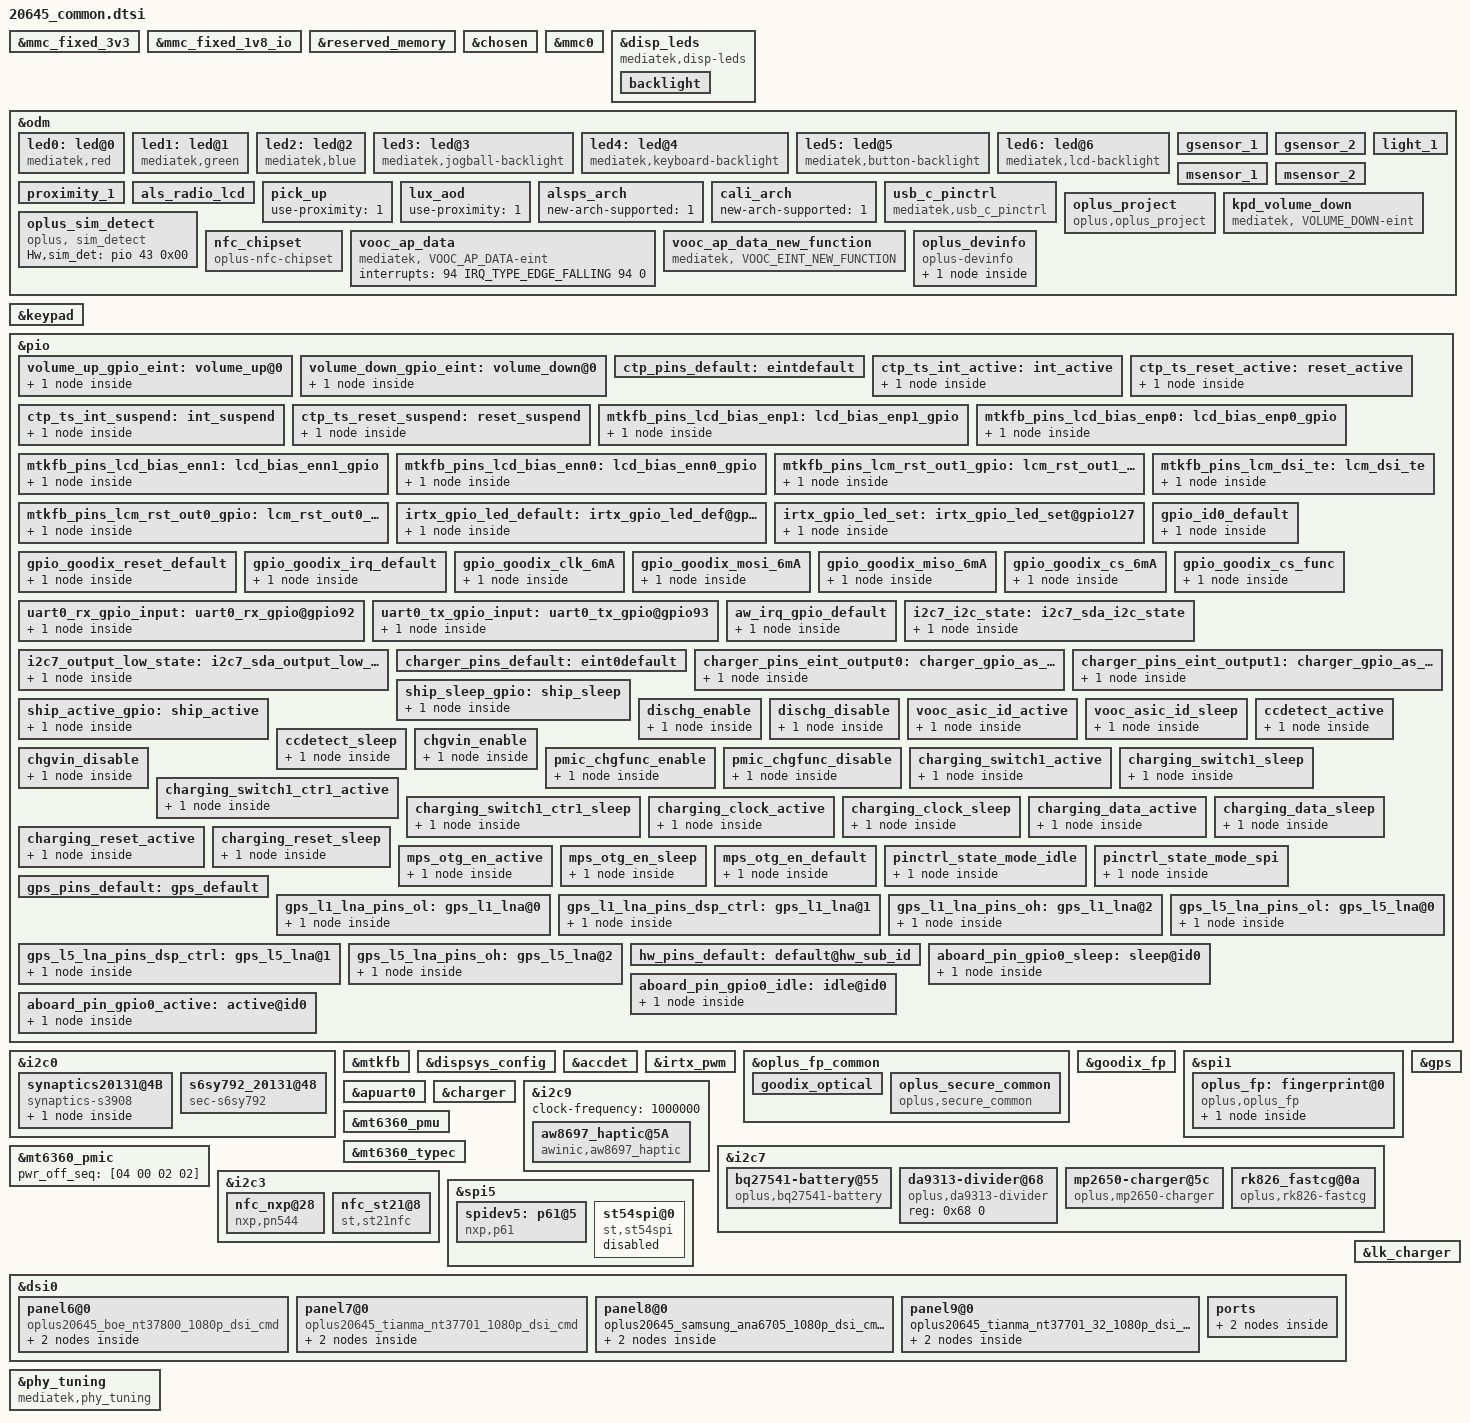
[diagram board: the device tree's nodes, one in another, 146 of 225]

&mmc_fixed_3v3 {
	status = "okay";
	regulator-name = "mmc_power";
	regulator-min-microvolt = <3300000>;
	regulator-max-microvolt = <3300000>;
	enable-active-high;
	regulator-always-on;
};

&mmc_fixed_1v8_io {
	status = "okay";
	regulator-name = "mmc_io";
	regulator-min-microvolt = <1800000>;
	regulator-max-microvolt = <1800000>;
	enable-active-high;
	regulator-always-on;
};

&reserved_memory {
};

/* chosen */
&chosen {

	atag,videolfb-fb_base_l = <0x7e020000>;
	atag,videolfb-fb_base_h = <0x0>;
	atag,videolfb-islcmfound = <1>;
	atag,videolfb-islcm_inited = <0>;
	atag,videolfb-fps= <6000>;
	atag,videolfb-vramSize= <0x1be0000>;
	atag,videolfb-lcmname=
		"nt35595_fhd_dsi_cmd_truly_nt50358_drv";
};

&mmc0 {
	status = "okay";
	/* pinctrl-names = "default", "state_uhs"; */
	/* pinctrl-0 = <&mmc0_pins_default>; */
	/* pinctrl-1 = <&mmc0_pins_uhs>; */
	bus-width = <8>;
	max-frequency = <5000000>;
	cap-mmc-highspeed;
	no-sdio;
	no-sd;
	vmmc-supply = <&mmc_fixed_3v3>;
	vqmmc-supply = <&mmc_fixed_1v8_io>;
	non-removable;
};

&disp_leds {
	compatible = "mediatek,disp-leds";
	backlight {
		label = "lcd-backlight";
		max-brightness = <4095>;
		led-bits = <12>;
		trans-bits = <12>;
		default-state = "on";
	};
};

&odm {
	led0:led@0 {
		compatible = "mediatek,red";
		led_mode = <0>;
		data = <1>;
		pwm_config = <0 0 0 0 0>;
	};
	led1:led@1 {
		compatible = "mediatek,green";
		led_mode = <0>;
		data = <1>;
		pwm_config = <0 0 0 0 0>;
	};
	led2:led@2 {
		compatible = "mediatek,blue";
		led_mode = <0>;
		data = <1>;
		pwm_config = <0 0 0 0 0>;
	};
	led3:led@3 {
		compatible = "mediatek,jogball-backlight";
		led_mode = <0>;
		data = <1>;
		pwm_config = <0 0 0 0 0>;
	};
	led4:led@4 {
		compatible = "mediatek,keyboard-backlight";
		led_mode = <0>;
		data = <1>;
		pwm_config = <0 0 0 0 0>;
	};
	led5:led@5 {
		compatible = "mediatek,button-backlight";
		led_mode = <0>;
		data = <1>;
		pwm_config = <0 0 0 0 0>;
	};
	led6:led@6 {
		compatible = "mediatek,lcd-backlight";
		//led_mode = <5>;
		//#else
		led_mode = <4>;
		//#endif
		data = <1>;
		pwm_config = <0 1 0 0 0>;
	};

/* sensor start */
	/*
	enum {
		LIS3DH,
		LSM6DS3,
		BMI160,
		LIS2HH12,
		LSM6DSM,
		BMI2XY,
		LSM6DSO,
	};
	*/
	gsensor_1: gsensor_1 {
		status = "okay";
		sensor_name = <2>;//BMI160
		device_name = "bmi160";
		i2c_num = <2>;
		i2c_addr = <0>;
		direction = <7>;
		eint_num = <3>;
		step_count_7_en = <1>;
		config_miso = <1>;
		correct_y_bias = <0>;
		gyro_cali_version= <2>;
		acc_cali_range= <250 250 250>; //250mg
	};
	gsensor_2: gsensor_2 {
		status = "okay";
		sensor_name = <4>;//LSM6DS3_c
		device_name = "lsm6ds3";
		i2c_num = <2>;
		i2c_addr = <0>;
		direction = <6>;
		eint_num = <3>;
		gyro_cali_version= <2>;
		acc_cali_range= <200 200 200>; //250mg
	};
	/*
	enum {
		AKM09911,
		MMC3530,
		MMC5603,
		MXG4300,
	};
	*/
	msensor_1: msensor_1 {
		status = "okay";
		sensor_name = <0>;//AKM09911
		i2c_num = <0>;
		i2c_addr = <12>;
		direction = <1>;
		eint_num = <0>;
		soft-mag-parameter = <11168 0 285 1 86 1 218 1 9025 0 78 1 263 1 31 0 10658 0>;
	};
	msensor_2: msensor_2 {
		status = "okay";
		sensor_name = <2>;//MMC5603
		i2c_num = <0>;
		i2c_addr = <48>;
		direction = <1>;
		eint_num = <0>;
		soft-mag-parameter = <9988 0 131 0 26 0 769 1 7569 0 105 1 417 0 234 1 9811 0>;
	};
	/*
	enum {
		TMD2725,
		APSD9922,
		STK3335,
		STK3331,
		STK2232,
		TCS3701,
		STK32600,
	};
	*/
	proximity_1: proximity_1 {
		status = "okay";
		sensor_name = <5>;//TCS3701
		i2c_num = <0>;
		i2c_addr = <57>;
		direction = <4>;
		eint_num = <4>;
		low_step = <300>;
		high_step = <400>;
		low_limit = <400>;
		high_limit = <600>;
		dirty_low_step = <100>;
		dirty_high_step = <150>;
		ps_dirty_limit = <1022>;
		ps_ir_limit = <500>;
		ps_adjust_min = <0>;
		ps_adjust_max = <600>;
		sampling_count = <5>;
		step_max = <400>;
		step_min = <110>;
		step_div = <1500>;
		anti_shake_delta = <80>;
		dynamic_cali_max = <1023>;
		raw2offset_radio = <31200>;
		offset_max = <250>;
		offset_range_min = <255>;
		offset_range_max = <255>;
		force_cali_limit = <2000>;
		cali_jitter_limit = <30>;
		cal_offset_margin = <120>;
	};
	light_1: light_1 {
		status = "okay";
		sensor_name = <5>;//TCS3701
		i2c_num = <0>;
		i2c_addr = <57>;
		direction = <4>;
		eint_num = <4>;
		als_ratio = <200>;
		als_buffer_length =<10>;
		als_type = <2>;
		device_name = "tcs3701";
	};
	als_radio_lcd:als_radio_lcd {
		status = "okay";
		samsung_als_radio = <200>;
		boe_als_radio = <150>;
		tianma_als_radio = <150>;
	};
	pick_up: pick_up {
		status = "okay";
		use-proximity = <1>;
	};
	lux_aod: lux_aod {
		status = "okay";
		use-proximity = <1>;
	};
	alsps_arch: alsps_arch {
		status = "okay";
		new-arch-supported = <1>;
	};
	cali_arch: cali_arch {
		status = "okay";
		new-arch-supported = <1>;
	};
/* sensor end */
	usb_c_pinctrl:usb_c_pinctrl {
		compatible = "mediatek,usb_c_pinctrl";
	};
/*OPLUS_FEATURE_TP_BASIC oplus project start */
	oplus_project:oplus_project {
		compatible = "oplus,oplus_project";
	};
/*endif*/
//#ifdef OPLUS_FEATURE_TP_BASIC
        kpd_volume_down:kpd_volume_down {
                compatible = "mediatek, VOLUME_DOWN-eint";
                interrupt-parent = <&pio>;
                interrupts = <155 IRQ_TYPE_EDGE_FALLING 155 0>;
                debounce = <32000>;
                status = "okay";
        };

//#endif OPLUS_FEATURE_TP_BASIC

//#ifdef OPLUS_FEATURE_TP_BASIC
    oplus_sim_detect {
        compatible = "oplus, sim_detect";
        Hw,sim_det = <&pio 43 0x00>;
    };
//#endif /* OPLUS_FEATURE_TP_BASIC */

    nfc_chipset:nfc_chipset {
        compatible = "oplus-nfc-chipset";
        chipset-20645 = "SN100T";
        chipset-20649 = "SN100T";
    };
//#endif /* OPLUS_FEATURE_NFC_CONSOFT */
};
//#ifdef OPLUS_FEATURE_TP_BASIC
&keypad {
        keypad,volume-up        = <&pio 20 0x00>;
        keypad,volume-down      = <&pio 155 0x00>;
        pinctrl-names = "volume_up_as_int", "volume_down_as_int";
        pinctrl-0 = <&volume_up_gpio_eint>;
        pinctrl-1 = <&volume_down_gpio_eint>;
        status = "okay";
};

&pio {
        volume_up_gpio_eint:volume_up@0{
                pins_cmd_dat {
                        pinmux = <PINMUX_GPIO59__FUNC_GPIO59>;
                        slew-rate = <0>;  /*direction 0:in, 1:out*/
                        input-enable;
                };
        };

        volume_down_gpio_eint:volume_down@0{
                pins_cmd_dat {
                        pinmux = <PINMUX_GPIO155__FUNC_GPIO155>;
                        slew-rate = <0>;  /*direction 0:in, 1:out*/
                        input-enable;
                };
        };
};
//#endif OPLUS_FEATURE_TP_BASIC
//#ifdef OPLUS_FEATURE_TP_BASIC
&i2c0 {

	synaptics20131@4B {
		compatible = "synaptics-s3908";
		reg = <0x4B>;
		chip-name = "S3908";

		/* Interrupt && Irq-gpio */
		interrupt-parent = <&pio>;
		interrupts = <21 0x2008>;

		/* Power Config */
		vdd_2v8-supply  = <&mt_pmic_vtp_ldo_reg>;
		vdd_2v8_volt = <3000000>;
		/* Other HW Resource */

		irq-gpio = <&pio 21 0x2008>;
		reset-gpio = <&pio 20 0x1>;
		pinctrl-names = "default";
		pinctrl-0 = <&ctp_ts_int_active &ctp_ts_reset_suspend>;

		touchpanel,max-num-support = <10>;
                touchpanel,tx-rx-num = <16 36>;
                touchpanel,panel-coords = <5400 12000>;
                touchpanel,display-coords = <1080 2400>;
                touchpanel,touchmajor-limit = <160 270>;
		//touchpanel,elimination-range = <20 200 200>;
                touchpanel,int-mode = <1>; /*0: interrupt and disable, 1:interrupt and not disable*/
		touchpanel,smooth-level = <0 1 2 3 8 10>;
		touchpanel,sensitive-level = <0 88 70 64 45 10>;

		vid_len = <2>;
		tp_type = <3>; /*type:8 BOE*/
		platform_support_project = <20645 20649 0x2064A 0x2068D
                				20645 20649 0x2064A 0x2068D>;
		platform_support_project_dir = <20645 20645 20645 20645
                				20645 20645 20645 20645>;
		platform_support_project_commandline = "oplus20645_boe_nt37800_1080p_dsi_cmd","oplus20645_boe_nt37800_1080p_dsi_cmd","oplus20645_boe_nt37800_1080p_dsi_cmd","oplus20645_boe_nt37800_1080p_dsi_cmd","oplus20645_tianma_nt37701","oplus20645_tianma_nt37701","oplus20645_tianma_nt37701","oplus20645_tianma_nt37701";

		prevention,dead_area_width = <0 0>;
		prevention,makeup_cnt_weight = <4 1 2 2 1>;
		prevention,large_judge_para = <30 8 8>;
		prevention,large_corner_judge_para = <30 5 5 80 80 0>;

		prevention,curved_large_area_width = <500 500 400 3 3>;
		prevention,large_curved_long_judge_para = <7 180 30 15 15 7 4 7 5 3 3>;
		prevention,large_curved_short_judge_para = <6 180 30 0 15 7 4 7 5 2 3>;
		prevention,grip_large_detect_time = <175>;
		prevention,grip_down_delta_time = <150>;
		prevention,curved_screen;

		prevention,condition_judge_para = <40 30>;
		prevention,condition_area_width = <0 0 80 80>;
		prevention,large_area_width = <0 0>;
		prevention,large_corner_width = <0 0 0>;
		prevention,eli_area_width = <0 0 0 0 0 0>;
		prevention,grip_disable_level = <6>;

		/* SW Support Feature Control */
		health_monitor_v2_support;
		black_gesture_support;
		charger_pump_support;
		lcd_tp_refresh_support;
		fw_update_app_support;
		smart_gesture_support;
		game_switch_support;
		report_flow_unlock_support;
		kernel_grip_support;
		fingerprint_underscreen_support;
		headset_pump_support;
		pressure_report_support;
		irq_need_dev_resume_ok;
		touchpanel,single-optimized-time = <8>;
		report_rate_white_list_support;
		/*
		 *Virtual Key Config:
		 *1:touchpanel,button-type: <virtualkey_type  supportted_button-map>
		 *virtualkey_type:
		 *Type 1: using board_properties
		 *Type 2: using same IC (button zone&& touch zone are seprate)
		 *Type 3: using diffrent IC (button zone&& touch zone are seprate)
		 *Type 4: No need of virtual key process
		 *supportted_button-map:select|menu|home|back
		 *
		 *2:touchpanel,button-map
		 *type (X1,Y1)(X2,Y2)(X3,Y3)(Width_X,Hight_Y)--Only when button-type is 0
		 */
		touchpanel,button-type = <4>;
		touchpanel.button-TRx = <0 0>;

		S3908 {
			report_rate_default = <90>;
			report_rate_game_value = <2>;
		};
	};

	s6sy792_20131@48 {
		compatible = "sec-s6sy792";
		reg = <0x48>;
		chip-name = "S6SY792";

                /* Interrupt && Irq-gpio */
                interrupt-parent = <&pio>;
                interrupts = <21 0x2008>;

                /* Power Config */
                vdd_2v8-supply  = <&mt_pmic_vtp_ldo_reg>;
                vdd_2v8_volt = <3000000>;
                /* Other HW Resource */

                irq-gpio = <&pio 21 0x2008>;
                reset-gpio = <&pio 20 0x1>;
                pinctrl-names = "default";
                pinctrl-0 = <&ctp_ts_int_active &ctp_ts_reset_suspend>;

		touchpanel,max-num-support = <10>;
                touchpanel,tx-rx-num = <16 36>;
                touchpanel,panel-coords = <5400 12000>;
                touchpanel,display-coords = <1080 2400>;
                touchpanel,touchmajor-limit = <160 270>;
                //touchpanel,elimination-range = <20 200 200>;
		touchpanel,smooth-level = <255 0 2 4 5 6>;
		touchpanel,smooth-level-charging = <255 9 10 10 11 11>;
		touchpanel,sensitive-level = <255 20 15 10 5 1>;

                vid_len = <2>;
                tp_type = <8>; /*type:8 SAMSUNG*/
                platform_support_project = <20645 20649 0x2064A 0x2068D>;
        	platform_support_project_dir = <20645 20645 20645 20645>;
                platform_support_project_commandline = "oplus20645_samsung_ana6705_1080p_dsi_cmd","oplus20645_samsung_ana6705_1080p_dsi_cmd","oplus20645_samsung_ana6705_1080p_dsi_cmd","oplus20645_samsung_ana6705_1080p_dsi_cmd";

		prevention,dead_area_width = <0 0>;
		prevention,makeup_cnt_weight = <4 1 2 2 1>;
		prevention,large_judge_para = <30 8 8>;
		prevention,large_corner_judge_para = <30 5 5 80 80 0>;

		prevention,curved_large_area_width = <500 500 400 3 3>;
		prevention,large_curved_long_judge_para = <6 180 30 15 15 7 4 7 5 3 3>;
		prevention,large_curved_short_judge_para = <6 180 30 0 15 7 4 7 5 2 3>;
		prevention,grip_large_detect_time = <175>;
		prevention,grip_down_delta_time = <125>;
		prevention,curved_screen;

		prevention,condition_judge_para = <40 30>;
		prevention,condition_area_width = <0 0 80 80>;
		prevention,large_area_width = <0 0>;
		prevention,large_corner_width = <0 0 0>;
		prevention,eli_area_width = <0 0 0 0 0 0>;
		prevention,grip_disable_level = <6>;

		/* SW Support Feature Control */
		health_monitor_v2_support;
		black_gesture_support;
		charger_pump_support;
		fw_update_app_support;
		smart_gesture_support;
		game_switch_support;
		kernel_grip_support;
		fingerprint_underscreen_support;
		headset_pump_support;
		pressure_report_support;
		irq_need_dev_resume_ok;
		sec_kernel_grip_para = <21000>;
		auto_test_need_cal_support;
		touchpanel,single-optimized-time = <8>;

                /*
                 *Virtual Key Config:
                 *1:touchpanel,button-type: <virtualkey_type  supportted_button-map>
                 *virtualkey_type:
                 *Type 1: using board_properties
                 *Type 2: using same IC (button zone&& touch zone are seprate)
                 *Type 3: using diffrent IC (button zone&& touch zone are seprate)
                 *Type 4: No need of virtual key process
                 *supportted_button-map:select|menu|home|back
                 *
                 *2:touchpanel,button-map
                 *type (X1,Y1)(X2,Y2)(X3,Y3)(Width_X,Hight_Y)--Only when button-type is 0
                 */
                touchpanel,button-type = <4>;
                touchpanel.button-TRx = <0 0>;
	};
};

&pio {
	ctp_pins_default: eintdefault {
	};
	ctp_ts_int_active: int_active {
		pins_cmd_dat {
			pinmux = <PINMUX_GPIO21__FUNC_GPIO21>;
			slew-rate = <0>;
			bias-pull-up;
		};
	};
	ctp_ts_reset_active: reset_active {
		pins_cmd_dat {
			pinmux = <PINMUX_GPIO20__FUNC_GPIO20>;
			slew-rate = <1>;
			output-high;
		};
	};
	ctp_ts_int_suspend: int_suspend {
		pins_cmd_dat {
			pinmux = <PINMUX_GPIO21__FUNC_GPIO21>;
			slew-rate = <1>;
			output-low;
		};
	};
	ctp_ts_reset_suspend: reset_suspend {
		pins_cmd_dat {
			pinmux = <PINMUX_GPIO20__FUNC_GPIO20>;
			slew-rate = <1>;
			output-low;
		};
	};
};
//#endif OPLUS_FEATURE_TP_BASIC

/* DISPSYS GPIO standardization */
&pio {
	mtkfb_pins_lcd_bias_enp1: lcd_bias_enp1_gpio {
		pins_cmd_dat {
			pinmux = <PINMUX_GPIO28__FUNC_GPIO28>;
			slew-rate = <1>;
			output-high;
		};
	};

	mtkfb_pins_lcd_bias_enp0: lcd_bias_enp0_gpio {
		pins_cmd_dat {
			pinmux = <PINMUX_GPIO28__FUNC_GPIO28>;
			slew-rate = <1>;
			output-low;
		};
	};

	mtkfb_pins_lcd_bias_enn1: lcd_bias_enn1_gpio {
		pins_cmd_dat {
			pinmux = <PINMUX_GPIO29__FUNC_GPIO29>;
			slew-rate = <1>;
			output-high;
		};
	};

	mtkfb_pins_lcd_bias_enn0: lcd_bias_enn0_gpio {
		pins_cmd_dat {
			pinmux = <PINMUX_GPIO29__FUNC_GPIO29>;
			slew-rate = <1>;
			output-low;
		};
	};

	mtkfb_pins_lcm_rst_out1_gpio: lcm_rst_out1_gpio {
		pins_cmd_dat {
			pinmux = <PINMUX_GPIO42__FUNC_GPIO42>;
			slew-rate = <1>;
			output-high;
		};
	};

	mtkfb_pins_lcm_rst_out0_gpio: lcm_rst_out0_gpio {
		pins_cmd_dat {
			pinmux = <PINMUX_GPIO42__FUNC_GPIO42>;
			slew-rate = <1>;
			output-low;
		};
	};

	mtkfb_pins_lcm_dsi_te: lcm_dsi_te {
		pins_cmd_dat {
			pinmux = <PINMUX_GPIO41__FUNC_DSI_TE>;
		};
	};
};

&mtkfb {
	pinctrl-names = "lcd_bias_enp1_gpio", "lcd_bias_enp0_gpio",
		"lcd_bias_enn1_gpio", "lcd_bias_enn0_gpio",
		"lcm_rst_out1_gpio", "lcm_rst_out0_gpio",
		"mode_te_te";
	pinctrl-0 = <&mtkfb_pins_lcd_bias_enp1>;
	pinctrl-1 = <&mtkfb_pins_lcd_bias_enp0>;
	pinctrl-2 = <&mtkfb_pins_lcd_bias_enn1>;
	pinctrl-3 = <&mtkfb_pins_lcd_bias_enn0>;
	pinctrl-4 = <&mtkfb_pins_lcm_rst_out1_gpio>;
	pinctrl-5 = <&mtkfb_pins_lcm_rst_out0_gpio>;
	pinctrl-6 = <&mtkfb_pins_lcm_dsi_te>;
	status = "okay";
};

&dispsys_config {
	pinctrl-names =
		"lcm_rst_out1_gpio", "lcm_rst_out0_gpio",
		"mode_te_te";
	pinctrl-0 = <&mtkfb_pins_lcm_rst_out1_gpio>;
	pinctrl-1 = <&mtkfb_pins_lcm_rst_out0_gpio>;
	pinctrl-2 = <&mtkfb_pins_lcm_dsi_te>;
	status = "okay";

	helper-value = <0>, /*MTK_DRM_OPT_STAGE*/
		<1>, /*MTK_DRM_OPT_USE_CMDQ*/
		<1>, /*MTK_DRM_OPT_USE_M4U*/
		<0>, /*MTK_DRM_OPT_SODI_SUPPORT*/
		<1>, /*MTK_DRM_OPT_IDLE_MGR*/
		<0>, /*MTK_DRM_OPT_IDLEMGR_SWTCH_DECOUPLE*/
		<1>, /*MTK_DRM_OPT_IDLEMGR_BY_REPAINT*/
		<0>, /*MTK_DRM_OPT_IDLEMGR_ENTER_ULPS*/
		<0>, /*MTK_DRM_OPT_IDLEMGR_KEEP_LP11*/
		<0>, /*MTK_DRM_OPT_DYNAMIC_RDMA_GOLDEN_SETTING*/
		<1>, /*MTK_DRM_OPT_IDLEMGR_DISABLE_ROUTINE_IRQ*/
		<0>, /*MTK_DRM_OPT_MET_LOG*/
		<1>, /*MTK_DRM_OPT_USE_PQ*/
		<1>, /*MTK_DRM_OPT_ESD_CHECK_RECOVERY*/
		<1>, /*MTK_DRM_OPT_ESD_CHECK_SWITCH*/
		<1>, /*MTK_DRM_OPT_PRESENT_FENCE*/
		<0>, /*MTK_DRM_OPT_RDMA_UNDERFLOW_AEE*/
		<0>, /*MTK_DRM_OPT_DSI_UNDERRUN_AEE*/
		<1>, /*MTK_DRM_OPT_HRT*/
		<1>, /*MTK_DRM_OPT_HRT_MODE*/
		<0>, /*MTK_DRM_OPT_DELAYED_TRIGGER*/
		<1>, /*MTK_DRM_OPT_OVL_EXT_LAYER*/
		<0>, /*MTK_DRM_OPT_AOD*/
		<1>, /*MTK_DRM_OPT_RPO*/
		<0>, /*MTK_DRM_OPT_DUAL_PIPE*/
		<0>, /*MTK_DRM_OPT_DC_BY_HRT*/
		<1>, /*MTK_DRM_OPT_OVL_WCG*/
		<0>, /*MTK_DRM_OPT_OVL_SBCH*/
		<1>, /*MTK_DRM_OPT_COMMIT_NO_WAIT_VBLANK*/
		<0>, /*MTK_DRM_OPT_MET*/
		<0>, /*MTK_DRM_OPT_REG_PARSER_RAW_DUMP*/
		<0>, /*MTK_DRM_OPT_VP_PQ*/
		<0>, /*MTK_DRM_OPT_GAME_PQ*/
		<0>, /*MTK_DRM_OPT_MMPATH*/
		<1>, /*MTK_DRM_OPT_HBM*/
		<0>, /*MTK_DRM_OPT_VDS_PATH_SWITCH*/
		<0>, /*MTK_DRM_OPT_LAYER_REC*/
		<1>, /*MTK_DRM_OPT_CLEAR_LAYER*/
		<1>, /*MTK_DRM_OPT_SF_PF*/
		<1>, /*MTK_DRM_OPT_PRIM_DUAL_PIPE*/
		<1>; /*MTK_DRM_OPT_DYN_MIPI_CHANGE*/
};
/* DISPSYS GPIO standardization end */

/* accdet start */
&accdet {
	/* accdet micbias voltage: 0x09:2.85v 0x08:2.8v 0x07,
	 * 2.7v;0x05,2.5v;0x02,1.9v
	 */
	accdet-mic-vol = <8>;
	/* accdet pwm_width, pwm_thresh, fall_delay, rise_delay
	 * debounce0, debounce1, debounce3, debounce4
	 * eint pwm_width, eint pwm_thresh
	 * eint deb(debounce0, debounce1, debounce2, debounce3), inv_debounce
	 */
	/*#ifdef OPLUS_ARCH_EXTENDS*/
	headset-mode-setting = <0x500 0x500 1 0x1f0
				0x2000 0x800 0x2000 0x44
				0x0 0x7
				0x5 0x9 0x9 0xd 0xe>;
	/*#else*/
	/*
	headset-mode-setting = <0x500 0x500 1 0x1f0
				0x800 0x800 0x20 0x44
				0x4 0x1
				0x5 0x3 0x3 0x5 0xe>;
	*/
	/*#endif OPLUS_ARCH_EXTENDS*/
	accdet-plugout-debounce = <1>;
	/*1:ACC mode, 2:low cost without in bias, 6:low cost with in bias*/
	accdet-mic-mode = <2>;
	/*0--MD_MAX--UP_MAX--DW_MAX*/
	/*#ifdef OPLUS_ARCH_EXTENDS*/
	headset-three-key-threshold = <0 82 170 306>;
	/*#else*/
	/*headset-three-key-threshold = <0 80 220 400>;*/
	/*#endif OPLUS_ARCH_EXTENDS*/
	headset-three-key-threshold-CDD = <0 121 192 600>;
	/*0--MD_MAX--VOICE_MAX--UP_MAX--DW_MAX*/
	headset-four-key-threshold = <0 58 121 192 400>;

	/* select VTH to 2v and 500k, use internal resitance */
	eint_use_ext_res = <0>;
	status = "okay";
	/* add that is to rm the unplug headset pop */
	remove_unplug_pop = <1>;
};
/* accdet end */

/* IRTX GPIO Start */
&irtx_pwm {
	pinctrl-names = "irtx_gpio_led_default", "irtx_gpio_led_set";
	pinctrl-0 = <&irtx_gpio_led_default>;
	pinctrl-1 = <&irtx_gpio_led_set>;
	status = "okay";
};
&pio {
	/* IRTX GPIO Settings -Start */
	/* default: GPIO0, output, high */
	irtx_gpio_led_default:irtx_gpio_led_def@gpio127 {
		pins_cmd_dat {
			pinmux = <PINMUX_GPIO127__FUNC_GPIO127>;
			slew-rate = <1>;
			bias-disable;
			output-low;
			input-schmitt-enable = <0>;
		};
	};

	irtx_gpio_led_set:irtx_gpio_led_set@gpio127 {
		pins_cmd_dat {
			pinmux = <PINMUX_GPIO127__FUNC_PWM_3>;
			slew-rate = <1>;
			output-high;
		};
	};
}; /* IRTX GPIO Settings -End */

/* FINGERPRINT start */
&oplus_fp_common {
    oplus,fp_gpio_num = <1>;
    oplus,fp_gpio_0 = <&pio 190 0x0>;
    pinctrl-names = "default";
    pinctrl-0 = <&gpio_id0_default>;
    goodix_optical {
        oplus,fp-id = <0>; // fp id mapping table
        vendor-chip = <11>; // please refer to the struct fp_vendor_t in oplus_fp_commmon.n
        eng-menu = "-1,-1"; // represents SNR, inclination test item in engineer menu, and 0/1 means off/on 
        chip-name = "G_OPTICAL_G3S";  // /proc/fp_id, will be displayed in engineer menu 
	};


//#ifdef OPLUS_FEATURE_SECURITY_COMMON
	oplus_secure_common:oplus_secure_common {
		compatible = "oplus,secure_common";
		oplus,sec_reg_num = <0>;
		oplus,sec_en_anti_reg = <0>;
		oplus,sec_override1_reg = <0>;
		oplus,override1_en_value = <0>;
	};
//#endif  OPLUS_FEATURE_SECURITY_COMMON

};

&pio{
	gpio_id0_default: gpio_id0_default {
		pins_cmd_dat {
			pinmux = <PINMUX_GPIO190__FUNC_GPIO190>;
			slew-rate = <0>;
			bias-pull-up = <00>;
			input-enable;
		};
	};
};

&goodix_fp {
	goodix,gpio_irq = <&pio 15 0x00>;
	goodix,gpio_reset = <&pio 14 0x00>;
	goodix,gpio_cs = <&pio 157 0x00>;
	pinctrl-names = "default", "gf_spi_drive_6mA", "gf_cs_func";
	pinctrl-0 = <&gpio_goodix_irq_default>, <&gpio_goodix_reset_default>;
	pinctrl-1 = <&gpio_goodix_clk_6mA>, <&gpio_goodix_mosi_6mA>, <&gpio_goodix_miso_6mA>, <&gpio_goodix_cs_6mA>;
	pinctrl-2 = <&gpio_goodix_cs_func>;
	status = "okay";
};

&spi1 {
#address-cells = <1>;
#size-cells = <0>;
status = "okay";
oplus_fp: fingerprint@0 {
		 compatible = "oplus,oplus_fp";
		 reg = <0>;
		 spi-max-frequency = <8000000>;
		 spi-id = <1>;
		 spi-irq = <15>;
		 spi-reg = <11010000>;
		 dvdd-supply = <&mt_pmic_vmch_ldo_reg>;
		 dvdd-config = <3300000 3300000 150000>;
		 power-num = <1>;
		 status = "okay";
		 power_source_1 {
			 power-mode = <1>;
			 power-name = "dvdd";
			 power-config = "dvdd-config";
			 delay-time = <0>;
		 };
	 };
};
// 1 = ldo power, refer to oplus_fp_common.h
&pio{
gpio_goodix_reset_default: gpio_goodix_reset_default {
				   pins_cmd_dat {
					   pinmux = <PINMUX_GPIO14__FUNC_GPIO14>;
					   slew-rate = <1>;
					   output-low;
				   };
			   };
gpio_goodix_irq_default: gpio_goodix_irq_default {
				 pins_cmd_dat {
					 pinmux = <PINMUX_GPIO15__FUNC_GPIO15>;
					 slew-rate = <0>;
					 bias-pull-down;
				 };
			 };
gpio_goodix_clk_6mA: gpio_goodix_clk_6mA {
			     pins_cmd_dat {
				      pinmux = <PINMUX_GPIO156__FUNC_SPI1_A_CLK>;
				      drive-strength = <2>;
			     };
		     };
gpio_goodix_mosi_6mA: gpio_goodix_mosi_6mA {
			      pins_cmd_dat {
				      pinmux = <PINMUX_GPIO159__FUNC_SPI1_A_MO>;
				      drive-strength = <2>;
			      };
		      };
gpio_goodix_miso_6mA: gpio_goodix_miso_6mA {
			      pins_cmd_dat {
				      pinmux = <PINMUX_GPIO158__FUNC_SPI1_A_MI>;
				      drive-strength = <3>;
			      };
		      };
gpio_goodix_cs_6mA: gpio_goodix_cs_6mA {
			    pins_cmd_dat {
				    pinmux = <PINMUX_GPIO157__FUNC_SPI1_A_CSB>;
				    drive-strength = <2>;
			    };
		    };
gpio_goodix_cs_func: gpio_goodix_cs_func {
			     pins_cmd_dat {
				     pinmux = <PINMUX_GPIO157__FUNC_SPI1_A_CSB>;
				     drive-strength = <2>;
			     };
		     };
};
//#endif
/* FINGERPRINT end */

&apuart0 {
	pinctrl-names = "uart0_rx_gpio",
			"uart0_tx_gpio";
	pinctrl-0 = <&uart0_rx_gpio_input>;
	pinctrl-1 = <&uart0_tx_gpio_input>;
	status = "okay";
};

&pio {
	uart0_rx_gpio_input:uart0_rx_gpio@gpio92 {
		pins_cmd_dat {
			pinmux = <PINMUX_GPIO92__FUNC_GPIO92>;
			input-enable;
			slew-rate = <0>;
			bias-disable;
		};
	};
	uart0_tx_gpio_input:uart0_tx_gpio@gpio93 {
		pins_cmd_dat {
			pinmux = <PINMUX_GPIO93__FUNC_GPIO93>;
			input-enable;
			slew-rate = <0>;
			bias-disable;
		};
	};
};

&charger {
	io-channels = <&auxadc 4>,
		<&auxadc 5>;
	io-channel-names = "auxadc4-usb_temp_v_l",
		"auxadc5-usb_temp_v_r";

	pinctrl-names = "default", "charger_gpio_as_output_low", "charger_gpio_as_output_high", "ship_sleep", "ship_active",
		"dischg_enable", "dischg_disable", "chgvin_enable", "chgvin_disable", "pmic_chgfunc_enable", "pmic_chgfunc_disable",
		"ccdetect_active","ccdetect_sleep";
	pinctrl-0 = <&charger_pins_default>;
	pinctrl-1 = <&charger_pins_eint_output0>;	//USB_ON -> USB_SWITCH:(UART && USB)
	pinctrl-2 = <&charger_pins_eint_output1>;
	pinctrl-3 = <&ship_sleep_gpio>;				//ship_mode
	pinctrl-4 = <&ship_active_gpio>;
	pinctrl-5 = <&dischg_enable>;				//usb_hightemp_port
	pinctrl-6 = <&dischg_disable>;
	pinctrl-7 = <&chgvin_enable>;					//EVB GPIO30 chgvin
	pinctrl-8 = <&chgvin_disable>;
	pinctrl-9 = <&pmic_chgfunc_enable>;				//EVB GPIO26 chg_enable
	pinctrl-10 = <&pmic_chgfunc_disable>;
	//pinctrl-5 = <&shortc_active_gpio>;
	pinctrl-11 = <&ccdetect_active>;
	pinctrl-12 = <&ccdetect_sleep>;
	qcom,hv_flashled_support;
	qcom,chargerid_support;
	qcom,smart_charging_screenoff;
	qcom,usbtemp_batttemp_gap = <18>;
	qcom,input_current_charger_ma = <2000>;
	qcom,pd_input_current_charger_ma = <2000>;
	qcom,qc_input_current_charger_ma = <2000>;
	qcom,input_current_usb_ma = <500>;

	qcom,input_current_led_ma = <1200>;
	qcom,input_current_led_ma_high = <1200>;
	qcom,input_current_led_ma_warm = <1500>;
	qcom,input_current_led_ma_normal = <2000>;
	qcom,led_warm_bat_decidegc = <350>;
	qcom,led_high_bat_decidegc = <370>;

	qcom,input_current_camera_ma = <1200>;
	qcom,input_current_cdp_ma = <1500>;

	qcom,input_current_vooc_led_ma_high = <1200>;
	qcom,input_current_vooc_led_ma_warm = <1800>;
	qcom,input_current_vooc_led_ma_normal = <3600>;
	qcom,input_current_vooc_ma_normal = <3600>;
	qcom,vooc_temp_bat_normal_decidegc = <350>;
	qcom,input_current_vooc_ma_warm = <3200>;
	qcom,vooc_temp_bat_warm_decidegc = <370>;
	qcom,input_current_vooc_ma_high = <2200>;
	qcom,vooc_temp_bat_hot_decidegc = <440>;

	qcom,charger_current_vooc_ma_normal = <1800>;

	qcom,chg_ctrl_by_calling;
	qcom,input_current_calling_ma = <1500>;

	qcom,overtemp_bat_decidegc = <350>;
	qcom,iterm_disabled = <0>;
	sw_full_count = <25>;
	qcom,iterm_ma = <125>;
	qcom,recharge-mv = <100>;
	qcom,batt_capacity_mah = <4500>;/*typical capacity*/

	qcom,removed_bat_decidegc = <190>;  /*<-19C*/

	qcom,cold_bat_decidegc = <20>;  /*-2C~0C*/
	qcom,temp_cold_vfloat_mv = <3980>;
	qcom,temp_cold_fastchg_current_ma = <300>;

	qcom,little_cold_bat_decidegc = <0>;    /*0C~5C*/
	qcom,temp_little_cold_vfloat_mv = <4435>;
	qcom,temp_little_cold_fastchg_current_ma_high = <1100>;
	qcom,temp_little_cold_fastchg_current_ma_low = <1100>;
	qcom,temp_little_cold_fastchg_current_ma = <920>;
	qcom,pd_temp_little_cold_fastchg_current_ma_high = <2000>;
	qcom,pd_temp_little_cold_fastchg_current_ma_low = <1400>;
	qcom,qc_temp_little_cold_fastchg_current_ma_high = <2000>;
	qcom,qc_temp_little_cold_fastchg_current_ma_low = <1400>;

	qcom,cool_bat_decidegc = <50>;  /*5C~12C*/
	qcom,temp_cool_vfloat_mv = <4435>;
	qcom,temp_cool_fastchg_current_ma_high = <1100>;
	qcom,temp_cool_fastchg_current_ma_low = <1100>;
	qcom,pd_temp_cool_fastchg_current_ma_high = <2000>;
	qcom,pd_temp_cool_fastchg_current_ma_low = <2000>;
	qcom,qc_temp_cool_fastchg_current_ma_high = <2000>;
	qcom,qc_temp_cool_fastchg_current_ma_low = <2000>;

	qcom,little_cool_bat_decidegc = <120>;  /*12C~16C*/
	qcom,temp_little_cool_vfloat_mv = <4435>;
	qcom,temp_little_cool_fastchg_current_ma = <1100>;
	qcom,pd_temp_little_cool_fastchg_current_ma = <2000>;
	qcom,qc_temp_little_cool_fastchg_current_ma = <2000>;

	qcom,normal_bat_decidegc = <160>;       /*16C~44C*/
	qcom,temp_normal_fastchg_current_ma = <2000>;
	qcom,temp_normal_vfloat_mv = <4435>;
	qcom,pd_temp_normal_fastchg_current_ma = <2000>;
	qcom,qc_temp_normal_fastchg_current_ma = <2000>;

	qcom,warm_bat_decidegc = <450>;         /*45C~53C*/ /*8pin Bat Vooc project need add 3 degree C*/
	qcom,temp_warm_vfloat_mv = <4130>;
	qcom,temp_warm_fastchg_current_ma = <600>;
	qcom,pd_temp_warm_fastchg_current_ma = <600>;
	qcom,qc_temp_warm_fastchg_current_ma = <600>;
	qcom,temp_warm_fastchg_current_ma_led_on = <250>;

	qcom,hot_bat_decidegc = <530>;

	qcom,non_standard_vfloat_mv = <3980>;
	qcom,non_standard_fastchg_current_ma = <512>;

	qcom,short_c_bat_cv_mv = <4330>;
	qcom,short_c_bat_vfloat_mv = <3800>;
	qcom,short_c_bat_fastchg_current_ma = <512>;

	qcom,cold_vfloat_sw_limit = <3930>;
	qcom,little_cold_vfloat_sw_limit = <4385>;
	qcom,cool_vfloat_sw_limit = <4385>;
	qcom,little_cool_vfloat_sw_limit = <4385>;
	qcom,normal_vfloat_sw_limit = <4385>;
	qcom,warm_vfloat_sw_limit = <4080>;
	qcom,non_standard_vfloat_sw_limit = <3930>;
	qcom,short_c_bat_vfloat_sw_limit = <3750>;

	qcom,max_chg_time_sec = <60480>;
	qcom,charger_hv_thr = <9900>;
	qcom,charger_recv_thr = <9500>;
	qcom,charger_lv_thr = <3400>;
	qcom,vbatt_full_thr = <4435>;
	qcom,vbatt_hv_thr = <4600>;
	qcom,vfloat_step_mv = <8>;
	qcom,non_standard_vfloat_over_sw_limit = <3990>;
	qcom,cold_vfloat_over_sw_limit = <3990>;
	qcom,little_cold_vfloat_over_sw_limit = <4445>;
	qcom,cool_vfloat_over_sw_limit = <4445>;
	qcom,little_cool_vfloat_over_sw_limit = <4445>;
	qcom,normal_vfloat_over_sw_limit = <4445>;
	qcom,warm_vfloat_over_sw_limit = <4140>;

	qcom,vbatt_power_off = <3300>;
	qcom,vbatt_soc_1 = <3310>;
	qcom,vooc_project = <3>;
	qcom,vbatt_num = <2>;
	qcom,new_ui_warning_support;
	qcom,ffc_support;
	qcom,dual_ffc;
	recharge_after_full;

	qcom,normal_vterm_hw_inc = <18>;
	qcom,non_normal_vterm_hw_inc = <18>;

	qcom,ff1_normal_fastchg_ma = <550>;
	qcom,ff1_warm_fastchg_ma = <550>;

	qcom,ffc2_normal_fastchg_ma = <350>;/*12C~35c*/
	qcom,ffc2_temp_warm_decidegc = <350>;
	qcom,ffc2_warm_fastchg_ma = <350>;/*35C~40c*/
	qcom,ffc2_temp_high_decidegc = <400>;
	qcom,ffc2_temp_low_decidegc = <120>;

	qcom,ff1_exit_step_ma = <150>;
	qcom,ff1_warm_exit_step_ma = <150>;
	qcom,ffc2_exit_step_ma = <150>;
	qcom,ffc2_warm_exit_step_ma = <150>;

	qcom,ffc_normal_vfloat_sw_limit = <4445>;	/*exit*/
	qcom,ffc_temp_normal_vfloat_mv = <4500>;	/*vfloat*/
	qcom,ffc_normal_vfloat_over_sw_limit = <4500>;	/*vfloat*/

	qcom,ffc_warm_vfloat_sw_limit = <4445>;
	qcom,ffc_temp_warm_vfloat_mv = <4500>;
	qcom,ffc_warm_vfloat_over_sw_limit = <4500>;

	qcom,ffc2_normal_vfloat_sw_limit = <4440>;
	qcom,ffc2_temp_normal_vfloat_mv = <4500>;
	qcom,ffc2_normal_vfloat_over_sw_limit = <4500>;

	qcom,ffc2_warm_vfloat_sw_limit = <4435>;
	qcom,ffc2_temp_warm_vfloat_mv = <4500>;
	qcom,ffc2_warm_vfloat_over_sw_limit = <4500>;

	qcom,default_iterm_ma = <125>;
	qcom,default_temp_normal_fastchg_current_ma = <1000>;
	qcom,default_normal_vfloat_sw_limit = <4385>;
	qcom,default_temp_normal_vfloat_mv = <4435>;
	qcom,default_normal_vfloat_over_sw_limit = <4445>;

	qcom,default_temp_little_cool_fastchg_current_ma = <1100>;
	qcom,default_little_cool_vfloat_sw_limit = <4385>;
	qcom,default_temp_little_cool_vfloat_mv = <4435>;
	qcom,default_little_cool_vfloat_over_sw_limit = <4445>;

	qcom,vooc_show_ui_soc_decimal;
	qcom,ui_soc_decimal_speedmin = <20>;//2A
	qcom,check_batt_full_by_sw;
	qcom,external_gauge;
	qcom,chg_ctrl_by_lcd;
	qcom,chg_ctrl_by_vooc;
	qcom,chg_ctrl_by_camera;
	qcom,support_ntc_01c_precision;
	qcom,sw_vfloat_over_protect_enable;

	//for PD9V or QC9V
	qcom,vbatt_pdqc_to_5v_thr = <4100>;
	qcom,vbatt_pdqc_to_9v_thr = <4000>;

	//GPIO config:
	qcom,chargerid_switch-gpio = <&pio 192 0x00>;	//check
	qcom,ship-gpio = <&pio 126 0x00>;		//check
	qcom,dischg-gpio = <&pio 51 0x00>;		//check
	//qcom,shortc-gpio = <&pio 121 0x00>;
	qcom,ccdetect-gpio = <&pio 5 0x00>;

	//Lukaili Add for camera flash led
	qcom,chgvin = <&pio 30 0x00>;		//check
	qcom,pmic_chgfunc = <&pio 26 0x00>;		//check
};

&i2c9 {
    status = "okay";
	clock-frequency = <1000000>;
	
	/* AWINIC AW8697 Haptic */
	aw8697_haptic@5A {
		status = "okay";
		compatible = "awinic,aw8697_haptic";
		reg = <0x5A>;
		reset-gpio = <&pio 110 0x00>;
		irq-gpio = <&pio 8 0x00>;
		qcom,device_id = <832>;//19065

		pinctrl-names = "default";
		pinctrl-0 = <&aw_irq_gpio_default>;
	};
};

&pio{
	aw_irq_gpio_default: aw_irq_gpio_default {		//check
		pins_cmd_dat {
			pinmux = <PINMUX_GPIO8__FUNC_GPIO8>;
			input-enable;
			slew-rate = <0>;
			bias-pull-up;
		};
	};

};

&odm {
	vooc_ap_data:vooc_ap_data {
		compatible = "mediatek, VOOC_AP_DATA-eint";
		interrupts = <94 IRQ_TYPE_EDGE_FALLING 94 0>;
	};
	vooc_ap_data_new_function:vooc_ap_data_new_function {
		compatible = "mediatek, VOOC_EINT_NEW_FUNCTION";
	};
};

&i2c7 {
       pinctrl-names = "i2c-state", "output-low-state";

       pinctrl-0 = <&i2c7_i2c_state>;
       pinctrl-1 = <&i2c7_output_low_state>;
};
&pio {
       i2c7_i2c_state: i2c7_sda_i2c_state {
                pins_cmd_dat {
                          pinmux = <PINMUX_GPIO125__FUNC_SDA7>;
                          slew-rate = <0>;
                          bias-pull-up = <11>;
                };
       };
       i2c7_output_low_state: i2c7_sda_output_low_state {
                pins_cmd_dat {
                          pinmux = <PINMUX_GPIO125__FUNC_GPIO125>;
                          slew-rate = <1>;
                          output-low;
                };
       };
};
&i2c7 {
	status = "okay";
	clock-frequency = <100000>;

	bq27541-battery@55 {
		status = "okay";
		compatible = "oplus,bq27541-battery";
		reg = <0x55 0>;
		qcom,modify-soc-smooth;
		qcom,modify-soc-calibration;
		qcom,batt_bq28z610 = <1>;
		qcom,sha1_key_index = <1>;
        //qcom,bq28z610_need_balancing;
	};

	da9313-divider@68 {
		status = "okay";
		compatible = "oplus,da9313-divider";
		reg = <0x68 0>;
	};

	mp2650-charger@5c {
		status = "okay";
		compatible = "oplus,mp2650-charger";
		reg = <0x5c 0>;

		qcom,mps_otg_en-gpio = <&pio 129 0x00>;		//check
		pinctrl-names = "mps_otg_en_active", "mps_otg_en_sleep", "mps_otg_en_default";
		pinctrl-0 = <&mps_otg_en_active>;
		pinctrl-1 = <&mps_otg_en_sleep>;
		pinctrl-2 = <&mps_otg_en_default>;
	};

	rk826_fastcg@0a{
		status = "okay";
		compatible = "oplus,rk826-fastcg";
		reg = <0x0a 0>;
		qcom,oplus_batt_4400mv;
		qcom,support_vooc_by_normal_charger_path;
		qcom,vooc-fw-type = <0x22>;
		qcom,vooc_reply_mcu_bits = <7>;
		qcom,vooc-low-temp = <0>;
		qcom,vooc-high-temp = <430>;
		qcom,vooc-low-soc = <1>;
		qcom,vooc-high-soc = <90>;

		qcom,vooc_cool_bat_volt = <3450>;
		qcom,vooc_little_cool_bat_volt = <3400>;
		qcom,vooc_normal_bat_volt = <3350>;
		qcom,vooc_warm_bat_volt = <3300>;

		qcom,vooc_cool_bat_suspend_volt = <3450>;
		qcom,vooc_little_cool_bat_suspend_volt = <3400>;
		qcom,vooc_normal_bat_suspend_volt = <3350>;
		qcom,vooc_warm_bat_suspend_volt = <3300>;

		qcom,vooc-little-cool-temp = <160>;
		qcom,vooc-cool-temp = <120>;
		qcom,vooc-little-cool-to-normal-temp = <180>;
		qcom,vooc-normal-to-little-cool-current = <0x05>;//5A
		
		qcom,vooc_multistep_adjust_current_support;
		qcom,vooc_multistep_initial_batt_temp = <1000>;
		qcom,vooc_strategy_normal_current = <0x0c>;
		qcom,vooc_batt_over_high_temp = <440>;
		qcom,vooc_batt_over_low_temp = <45>;
		qcom,vooc_over_high_or_low_current = <0x0>;

		qcom,vooc_strategy1_batt_high_temp0 = <400>;
		qcom,vooc_strategy1_batt_high_temp1 = <420>;
		qcom,vooc_strategy1_batt_high_temp2 = <430>;
		qcom,vooc_strategy1_batt_low_temp2 = <420>;
		qcom,vooc_strategy1_batt_low_temp1 = <410>;
		qcom,vooc_strategy1_batt_low_temp0 = <390>;

		qcom,vooc_strategy1_high_current0 = <0x09>;  //5A
		qcom,vooc_strategy1_high_current1 = <0x07>;  // 4A
		qcom,vooc_strategy1_high_current2 = <0x05>;  // 3A
		qcom,vooc_strategy1_low_current2 = <0x07>;   // 4A
		qcom,vooc_strategy1_low_current1 = <0x09>;   // 5A
		qcom,vooc_strategy1_low_current0 = <0x0c>;   // 0x0c

		qcom,vooc_strategy2_batt_up_temp1 = <400>;
		qcom,vooc_strategy2_batt_up_down_temp2 = <400>;
		qcom,vooc_strategy2_batt_up_temp3 = <410>;
		qcom,vooc_strategy2_batt_up_down_temp4 = <410>;
		qcom,vooc_strategy2_batt_up_temp5 = <420>;
		qcom,vooc_strategy2_batt_up_temp6 = <440>;
		qcom,vooc_strategy2_high0_current = <0x09>;
		qcom,vooc_strategy2_high1_current = <0x07>;
		qcom,vooc_strategy2_high2_current = <0x05>;
		qcom,vooc_strategy2_high3_current = <0x03>;

		qcom,vooc_current_lvl = <1000
									1500
									2000
									2500
									3000
									3500
									4000
									4500
									5000
									5500
									6000
									6500
									7000
									7500
									8000
									8500
									9000
									9500
									10000
									10500
									11000
									11500
									12000
									12500>;
		pinctrl-names = "switch1_act_switch2_act", "switch1_sleep_switch2_sleep",
						"switch1_act_switch3_act", "switch1_sleep_switch3_sleep",
						"switch1_act_switch2_sleep", "switch1_sleep_switch2_act",
						"clock_active","clock_sleep",
						"data_active","data_sleep",
						"reset_active","reset_sleep",
						"charging_switch1_ctr1_active","charging_switch1_ctr1_sleep",
						"vooc_asic_id_active","vooc_asic_id_sleep";
		pinctrl-0 = <&charging_switch1_active>;
		pinctrl-1 = <&charging_switch1_sleep>;
		pinctrl-2 = <&charging_switch1_active>;
		pinctrl-3 = <&charging_switch1_sleep>;
		pinctrl-4 = <&charging_switch1_active>;
		pinctrl-5 = <&charging_switch1_sleep>;
		pinctrl-6 = <&charging_clock_active>;
		pinctrl-7 = <&charging_clock_sleep>;
		pinctrl-8 = <&charging_data_active>;
		pinctrl-9 = <&charging_data_sleep>;
		pinctrl-10 = <&charging_reset_active>;
		pinctrl-11 = <&charging_reset_sleep>;
		pinctrl-12 = <&charging_switch1_ctr1_active>;
		pinctrl-13 = <&charging_switch1_ctr1_sleep>;
		pinctrl-14 = <&vooc_asic_id_active>;
		pinctrl-15 = <&vooc_asic_id_sleep>;

		qcom,charging_switch1-gpio 		= <&pio 191 0x00>;		//check
		qcom,charging_switch1_ctr1-gpio 	= <&pio 163 0x00>;	//empty
		//qcom,charging_switch2-gpio 		= <&tlmm 113 0x00>;
		//qcom,charging_switch3-gpio 		= <&tlmm 38 0x00>;

		qcom,charging_reset-gpio 			= <&pio 189 0x00>;		//check
		qcom,charging_clock-gpio 			= <&pio 95 0x00>;		//check
		qcom,charging_data-gpio 			= <&pio 94 0x00>;		//check
		qcom,vooc_asic_id-gpio				= <&pio 187 0x00>;
		
		qcom,parse_fw_from_dt;
		vooc,firmware_data = [
			00 00 34 55 f4 32 00 00 64 00 00 00 64 00 00 00 5a 4f 2f b7 4b be 2f 0d 00 00 00 00 00 00 00 00 

			00 00 00 00 00 00 00 00 00 00 00 00 00 00 00 00 00 00 00 00 00 00 00 00 00 00 00 00 00 00 00 00 

			00 00 00 00 00 00 00 00 00 00 00 00 00 00 00 00 00 00 00 00 00 00 00 00 00 00 00 00 00 00 00 00 

			00 00 00 00 00 00 00 00 00 00 00 00 00 00 00 00 00 00 00 00 00 00 00 00 00 00 00 00 00 00 00 00 

			00 08 00 20 0d 01 00 21 75 09 00 21 45 09 00 21 00 00 00 00 00 00 00 00 00 00 00 00 00 00 00 00 

			00 00 00 00 00 00 00 00 00 00 00 00 f7 09 00 21 00 00 00 00 00 00 00 00 f5 09 00 21 f9 09 00 21 

			2f 01 00 21 dd 08 00 21 2f 01 00 21 fd 09 00 21 2f 01 00 21 2f 01 00 21 2f 01 00 21 2f 01 00 21 

			15 0b 00 21 2f 01 00 21 2f 01 00 21 2f 01 00 21 03 48 85 46 00 f0 c2 fb 00 48 00 47 3d 1d 00 21 

			00 08 00 20 40 1e fd d8 70 47 00 00 08 48 09 49 01 60 08 20 c0 00 01 20 80 f3 10 88 00 bf 00 bf 

			05 48 00 47 fe e7 fe e7 fe e7 fe e7 fe e7 fe e7 00 00 02 50 00 80 00 80 f1 00 00 21 30 b5 0b 46 

			01 46 00 20 20 22 01 24 09 e0 0d 46 d5 40 9d 42 05 d3 1d 46 95 40 49 1b 25 46 95 40 40 19 15 46 

			52 1e 00 2d f1 dc 30 bd 70 b5 00 24 25 46 00 28 01 da 01 24 40 42 00 29 01 da 01 25 49 42 ff f7 

			dd ff ac 42 00 d0 40 42 00 2c 00 d0 49 42 70 bd f8 b5 02 46 4a 40 d4 0f 42 00 4b 00 52 08 5b 08 

			9a 42 02 d2 02 46 08 46 11 46 4a 00 23 d0 c3 0d 4a 00 dd b2 12 0e ad 1a 20 2d 35 da 49 02 01 26 

			49 0a f6 05 8a 19 00 2c 00 d0 52 42 20 21 4f 1b 11 46 b9 40 2a 41 10 18 c2 0d 9a 42 21 d0 00 2c 

			17 d0 01 2d 08 dc da 05 80 1a d2 0f 80 19 d2 07 db b2 00 f0 aa fa f8 bd da 05 80 1a 01 23 40 00 

			1b 06 c0 18 80 18 5a 42 80 18 ca 0f 10 43 49 00 07 e0 49 08 c2 07 11 43 da 05 80 1a 80 19 40 08 

			80 18 00 f0 8a fa f8 bd 61 00 01 22 51 1a 00 1b f7 e7 01 22 d2 07 51 40 aa e7 01 22 d2 07 50 40 

			a6 e7 02 46 70 b5 4a 40 d3 0f db 07 40 00 2d d0 4a 00 2a d0 01 0e 14 0e 00 02 12 02 09 19 40 0a 

			52 0a 84 18 e5 01 04 46 54 43 00 0a 12 0a 2e 04 50 43 a4 19 42 19 20 0c c5 43 aa 18 12 0c 01 25 

			ad 03 52 1c 52 19 12 04 7f 39 24 04 00 d0 52 1c 10 43 01 d4 40 00 49 1e c2 b2 0c 06 c0 09 20 18 

			40 1c 40 08 80 2a 02 d0 03 e0 00 20 70 bd 40 08 40 00 00 29 00 da 00 20 18 43 70 bd 70 b5 02 46 

			4a 40 d5 0f 40 00 4a 00 ed 07 40 08 52 08 00 28 14 d0 00 2a 12 d0 c4 0d d3 0d 41 02 01 20 c0 05 

			52 02 49 0a 52 0a e4 1a 09 18 12 18 7d 34 91 42 01 d3 64 1c 00 e0 49 00 00 2c 01 da 00 20 70 bd 

			00 23 91 42 01 d3 89 1a 03 43 40 08 49 00 00 28 f7 d1 00 29 0a d0 91 42 02 d1 01 21 c9 07 05 e0 

			91 42 01 d2 01 21 01 e0 01 21 c9 43 e0 05 c0 18 40 19 00 f0 02 fa 70 bd f0 b5 07 46 08 46 58 40 

			87 b0 c0 0f 04 90 48 00 0e 46 59 00 40 08 49 08 bc 1a 88 41 05 d2 38 46 31 46 1e 46 17 46 0b 46 

			02 46 58 00 40 08 10 43 4c d0 30 0d 03 90 40 05 59 00 40 0d 49 0d 05 90 40 1a 02 90 40 28 72 da 

			18 03 01 21 00 0b 09 05 08 43 01 90 04 98 00 92 00 28 05 d0 01 99 52 42 00 20 88 41 00 92 01 90 

			02 98 40 21 0a 1a 01 99 00 98 00 f0 a3 f9 05 46 0c 46 6b 46 07 cb 00 f0 ad f9 c0 19 71 41 03 9a 

			0e 0d 00 23 d7 17 56 40 1a 46 7a 40 16 43 44 d0 04 9a 00 2a 2d d0 02 9a 01 2a 03 9a 15 dc 12 05 

			c0 1a 91 41 01 26 36 05 00 1c 71 41 d2 0f 05 9e d2 07 00 93 01 92 02 96 2a 46 23 46 00 f0 eb f9 

			07 b0 f0 bd 38 46 31 46 fa e7 16 05 22 4a 0f 46 b2 18 c0 1a b7 41 01 21 09 05 00 1c 4f 41 00 18 

			7f 41 11 46 18 18 79 41 e2 0f 10 43 6d 19 64 41 13 e0 e2 07 6d 08 15 43 64 08 c2 07 14 43 03 9a 

			01 26 12 05 c0 1a 91 41 36 05 00 1c 71 41 ce 07 40 08 30 43 49 08 c0 18 51 41 2a 46 23 46 00 f0 

			ad f9 cd e7 ff e7 04 98 01 22 40 00 c1 17 12 1a 00 23 8b 41 04 98 31 46 c4 17 38 1a a1 41 ee e7 

			30 b4 01 24 e4 07 63 40 30 bc 55 e7 30 b4 01 24 e4 07 61 40 30 bc 4f e7 00 00 e0 ff f0 b5 1f b4 

			88 b0 0b 99 09 98 00 24 48 40 09 99 c0 0f 49 00 49 08 09 91 c0 07 0b 99 00 90 49 00 49 08 0b 91 

			09 99 08 98 a6 46 08 43 1c d0 0b 99 0a 98 08 43 18 d0 09 98 01 24 40 00 42 0d 48 00 41 0d 09 98 

			24 05 00 03 00 0b 20 43 09 90 0b 98 00 03 00 0b 20 43 0b 90 50 18 1c 49 40 18 00 22 01 90 14 46 

			10 46 05 e0 00 20 01 46 0d b0 f0 bd 03 28 01 da 03 46 00 e0 03 23 9c 46 c1 1a 0a ae 0a e0 5f 00 

			08 ad ed 5b 4f 00 f7 5b 7d 43 00 27 aa 18 7c 41 49 1c 5b 1e 61 45 f2 dd 41 00 04 ab 5a 52 21 04 

			12 0c 0a 43 24 0c 40 1c 08 28 df db 01 98 02 90 00 99 70 46 01 91 00 90 05 9b 04 9a 07 99 06 98 

			00 f0 39 f9 d0 e7 00 00 0d fc ff ff f0 b5 0c 46 5c 40 85 b0 e4 0f e4 07 03 94 4c 00 00 26 64 08 

			59 00 94 46 49 08 02 46 02 96 22 43 21 d0 62 46 0a 43 1e d0 62 00 57 0d 4a 00 0e 03 23 03 55 0d 

			01 24 02 46 2c 49 24 05 78 1b 1b 0b 36 0b 40 18 23 43 26 43 61 46 00 90 1c 46 50 1a b4 41 03 d3 

			00 98 40 1c 00 90 02 e0 92 18 00 98 5b 41 00 28 03 da 00 20 01 46 05 b0 f0 bd 00 20 01 21 09 05 

			07 46 86 46 11 e0 64 46 1d 46 14 1b b5 41 06 d3 65 46 52 1b b3 41 74 46 07 43 0c 43 a6 46 cd 07 

			40 08 49 08 28 43 92 18 5b 41 05 46 0d 43 ea d1 10 46 18 43 13 d0 60 46 19 46 50 40 71 40 08 43 

			06 d0 60 46 10 1a b3 41 06 d2 01 22 00 23 06 e0 00 22 01 23 db 07 02 e0 01 22 d2 43 53 10 00 98 

			74 46 01 05 38 1c 61 41 02 9c 03 9d 00 19 69 41 00 f0 b4 f8 bf e7 00 00 fd 03 00 00 c2 17 c1 0f 

			50 40 10 b5 40 18 ca 07 96 23 00 21 00 f0 6d f8 10 bd 10 b5 00 22 96 23 11 46 00 f0 66 f8 10 bd 

			c2 0f d2 07 40 00 40 08 0b d0 c1 0d 07 23 db 01 c9 18 40 02 09 05 40 0a 11 43 c2 08 40 07 11 43 

			70 47 00 20 01 46 70 47 cb 0f db 07 49 00 10 b5 49 08 02 46 0a 43 07 d0 0a 0d 07 24 09 03 e4 01 

			09 0b 12 1b 00 2a 01 dc 00 20 10 bd c9 00 44 0f 0c 43 c1 00 e0 18 d2 05 80 18 00 f0 2e f8 10 bd 

			01 22 d2 07 00 28 00 db 10 1a 00 29 00 db 51 1a 81 42 70 47 10 b5 20 2a 04 db 01 46 20 3a 91 40 

			00 20 10 bd 91 40 20 23 9c 1a 03 46 e3 40 19 43 90 40 10 bd 10 b5 20 2a 06 db cb 17 08 46 20 3a 

			10 41 c1 17 0b 43 06 e0 0b 46 13 41 d0 40 20 24 a2 1a 91 40 08 43 19 46 10 bd 00 29 04 da 40 1c 

			49 00 01 d1 40 08 40 00 70 47 70 b4 00 24 05 0c 05 d1 10 24 00 04 02 d1 00 29 21 d0 11 24 05 0e 

			01 d1 00 02 08 34 05 0f 01 d1 00 01 24 1d 85 0f 01 d1 80 00 a4 1c 00 28 01 db 40 00 64 1c 00 29 

			08 d0 20 25 2e 1b 0d 46 f5 40 a1 40 00 d0 01 21 29 43 08 43 01 06 1b 1b 00 0a db 1d 02 d5 00 20 

			70 bc 70 47 db 05 18 18 80 18 00 29 f8 da 40 1c 49 00 f5 d1 70 bc 40 08 40 00 70 47 10 b5 00 2b 

			08 da 00 24 40 1c 61 41 92 18 5b 41 1a 43 01 d1 40 08 40 00 10 bd f0 b5 1f b4 82 b0 05 46 0c 00 

			03 d0 08 46 00 f0 a2 f9 02 e0 00 f0 9f f9 20 30 02 46 00 90 21 46 28 46 ff f7 7c ff 04 9b 05 9a 

			04 46 0f 46 18 43 11 43 08 43 14 d0 18 46 10 43 1b d0 00 98 40 21 0a 1a 18 46 05 99 00 f0 40 f8 

			05 46 0e 46 00 9a 05 99 04 98 ff f7 63 ff 08 43 05 d0 01 20 04 e0 20 46 39 46 07 b0 f0 bd 00 20 

			c1 17 05 43 0e 43 2c 43 37 43 00 99 0e 98 63 05 40 1a 79 05 e4 0a 00 22 0c 43 fd 0a 0a 30 02 d5 

			00 20 01 46 e9 e7 01 05 10 19 69 41 0c 9c 0d 9d 00 19 69 41 ff f7 a2 ff df e7 00 00 06 4c 01 25 

			06 4e 05 e0 e3 68 07 cc 2b 43 0c 3c 98 47 10 34 b4 42 f7 d3 ff f7 30 fc e8 32 00 21 f8 32 00 21 

			10 b5 20 2a 04 db 08 46 20 3a d0 40 00 21 10 bd 0b 46 d3 40 d0 40 20 24 a2 1a 91 40 08 43 19 46 

			10 bd 10 b5 04 46 20 01 00 09 ff f7 1b fc 10 bd 00 bf 01 46 40 1e 00 29 fb d1 70 47 10 b5 01 f0 

			25 ff 04 46 80 20 20 40 00 28 18 d0 80 20 01 f0 17 ff 10 48 00 78 00 28 07 d1 02 f0 61 fa 00 20 

			0d 49 08 70 01 20 0b 49 08 70 0c 48 00 78 02 28 02 d1 00 f0 3f f9 0c e0 00 f0 8e fc 09 e0 40 20 

			20 40 00 28 05 d0 40 20 01 f0 fa fe 01 20 04 49 08 70 10 bd 69 01 00 20 32 01 00 20 5b 01 00 20 

			11 01 00 20 00 bf fe e7 70 b5 04 46 0d 46 16 46 2b 46 32 46 21 46 55 20 01 f0 aa ff 70 bd 70 b5 

			04 46 0d 46 16 46 2b 46 32 46 21 46 55 20 02 f0 3d f8 70 bd 70 47 00 00 70 b5 00 21 00 23 0f 22 

			c4 78 00 2c 25 d0 19 4c e4 68 07 25 2d 02 2c 40 2c 1b 21 0a 04 24 63 1a 14 46 cc 40 22 46 44 78 

			9c 40 21 46 84 78 14 40 21 43 09 01 10 4c 03 25 2d 02 64 19 05 78 ad 00 61 51 04 78 e5 06 ed 0e 

			01 24 ac 40 05 78 6d 11 ad 00 09 4e ad 19 2c 60 0a e0 04 78 e5 06 ed 0e 01 24 ac 40 04 4d 80 35 

			06 78 76 11 b6 00 ac 51 70 bd 00 00 00 ed 00 e0 00 e1 00 e0 70 47 70 47 70 47 00 00 10 b5 00 20 

			02 f0 98 f8 37 48 00 88 00 28 05 d0 35 48 00 88 40 1e 34 49 08 80 15 e0 7d 20 c0 00 31 49 08 80 

			31 48 00 88 00 28 04 d0 2f 48 00 88 40 1e 2e 49 08 80 2e 48 00 88 00 28 04 d0 2c 48 00 88 40 1e 

			2a 49 08 80 2a 48 00 68 00 28 04 d0 28 48 00 68 40 1e 27 49 08 60 27 48 00 68 00 28 04 d0 25 48 

			00 68 40 1e 23 49 08 60 23 48 00 68 00 28 04 d0 21 48 00 68 40 1e 20 49 08 60 20 48 00 78 00 28 

			04 d0 1e 48 00 78 40 1e 1c 49 08 70 1c 48 00 68 00 28 04 d0 1a 48 00 68 40 1e 19 49 08 60 19 48 

			00 68 00 28 04 d0 17 48 00 68 40 1e 15 49 08 60 15 48 00 78 40 1c 14 49 08 70 08 46 00 78 c8 28 

			0e dd 00 20 08 70 11 48 00 78 00 28 05 d0 00 20 01 f0 ec f8 01 20 0e 49 08 70 01 20 0b 49 08 70 

			10 bd 00 00 34 01 00 20 36 01 00 20 38 01 00 20 3c 01 00 20 40 01 00 20 44 01 00 20 48 01 00 20 

			4c 01 00 20 50 01 00 20 32 01 00 20 1f 01 00 20 10 01 00 20 04 48 00 69 00 28 04 d0 01 20 02 49 

			48 61 76 20 c8 60 70 47 00 00 01 40 20 21 02 0c 01 d0 10 21 10 46 02 0a 01 d0 10 46 08 39 02 09 

			01 d0 10 46 09 1f 82 08 01 d0 10 46 89 1e 42 08 01 d0 88 1e 70 47 08 1a 70 47 30 b4 74 46 64 1e 

			25 78 64 1c ab 42 04 d3 63 5d 5b 00 e3 18 30 bc 18 47 1d 46 f8 e7 02 e0 08 c8 12 1f 08 c1 00 2a 

			fa d1 70 47 70 47 00 20 01 e0 01 c1 12 1f 00 2a fb d1 70 47 10 b5 fe 48 00 78 08 28 0b da 01 f0 

			9b f8 fc 49 fa 4a 12 78 88 54 f9 48 00 78 40 1c f7 49 08 70 10 bd f6 48 00 78 08 28 26 d1 09 20 

			f3 49 08 70 02 f0 48 f8 f2 48 00 78 01 28 1e d1 f0 48 40 78 00 28 1a d1 ee 48 80 78 01 28 16 d1 

			ec 48 c0 78 c0 00 eb 49 09 79 89 00 08 43 e9 49 49 79 49 00 08 43 e7 49 89 79 08 43 e6 49 08 70 

			e6 48 00 78 00 28 6d d1 e5 49 08 70 6a e0 e1 48 00 78 01 28 1e d1 df 48 40 78 00 28 1a d1 dd 48 

			80 78 00 28 16 d1 db 48 c0 78 c0 00 d9 49 09 79 89 00 08 43 d7 49 49 79 49 00 08 43 d5 49 89 79 

			08 43 d5 49 08 70 00 20 d4 49 08 70 02 20 d4 49 08 70 47 e0 cf 48 40 78 01 28 1e d1 cd 48 80 78 

			00 28 1a d1 cb 48 c0 78 01 28 16 d1 c9 48 00 79 c0 00 c8 49 49 79 89 00 08 43 c6 49 89 79 49 00 

			08 43 c4 49 c9 79 08 43 c3 49 08 70 c3 48 00 78 00 28 01 d1 c2 49 08 70 8c e7 be 48 40 78 01 28 

			1e d1 bc 48 80 78 00 28 1a d1 ba 48 c0 78 00 28 16 d1 b8 48 00 79 c0 00 b6 49 49 79 89 00 08 43 

			b4 49 89 79 49 00 08 43 b2 49 c9 79 08 43 b2 49 08 70 00 20 b1 49 08 70 02 20 b1 49 08 70 69 e7 

			02 f0 32 f8 af 48 00 78 00 28 14 d1 ae 49 c8 70 08 71 48 71 88 71 c8 71 08 72 48 72 ab 48 00 78 

			02 28 09 d1 a4 48 00 78 00 07 00 0e a8 49 08 70 01 20 a5 49 48 71 02 e2 a4 48 00 78 01 28 0a d1 

			a3 48 00 78 9c 49 09 78 08 43 a1 49 08 70 01 20 9d 49 48 71 f3 e1 9f 48 00 78 05 28 16 d1 9a 48 

			80 7a 99 49 c8 70 08 46 c0 7a 08 71 08 46 00 7b 48 71 08 46 40 7b 88 71 08 46 80 7b c8 71 08 46 

			c0 7b 08 72 08 46 00 7c 48 72 d8 e1 91 48 00 78 04 28 09 d1 88 48 00 78 00 07 00 0c 8e 49 08 80 

			01 20 89 49 48 71 ca e1 8a 48 00 78 03 28 0b d1 81 48 00 78 00 02 88 49 09 88 08 43 86 49 08 80 

			01 20 81 49 48 71 ba e1 82 48 00 78 02 28 0b d1 79 48 00 78 00 01 80 49 09 88 08 43 7e 49 08 80 

			01 20 79 49 48 71 aa e1 7a 48 00 78 01 28 15 d1 79 48 00 88 70 49 09 78 08 43 77 49 08 80 00 f0 

			2d fb 01 20 70 49 48 71 74 48 00 88 72 49 09 88 88 42 90 d1 01 20 72 49 08 70 90 e1 71 48 00 78 

			00 28 4c d0 6f 48 00 78 40 1e c1 00 08 1a 6e 49 09 68 08 5c 64 49 c8 70 6a 48 00 78 40 1e c1 00 

			08 1a 69 49 09 68 40 18 40 78 5f 49 08 71 65 48 00 78 40 1e c1 00 08 1a 63 49 09 68 40 18 80 78 

			59 49 48 71 5f 48 00 78 40 1e c1 00 08 1a 5e 49 09 68 40 18 c0 78 54 49 88 71 5a 48 00 78 40 1e 

			c1 00 08 1a 58 49 09 68 40 18 00 79 4e 49 c8 71 54 48 00 78 40 1e c1 00 08 1a 53 49 09 68 40 18 

			40 79 49 49 08 72 4f 48 00 78 40 1e c1 00 08 1a 4d 49 09 68 40 18 80 79 43 49 48 72 3f e1 3e 48 

			00 78 09 28 0c d1 00 20 40 49 08 70 41 49 08 70 44 49 08 70 00 f0 fa fe 01 20 44 49 08 70 79 e6 

			00 20 3a 49 08 70 3b 49 08 70 3e 49 08 70 32 48 00 78 03 00 ff f7 41 fe 0e 08 0b 86 a2 d5 e8 22 

			22 22 22 22 22 f2 f0 22 01 f0 2e ff 62 e6 38 48 00 78 00 28 13 d0 37 48 00 78 00 28 06 d1 01 20 

			29 49 c8 70 08 71 08 72 48 72 02 e0 01 20 26 49 88 71 30 48 00 78 c0 43 2e 49 08 70 fe e0 2e 48 

			00 78 00 28 0e d0 01 20 1f 49 c8 70 08 71 48 71 88 71 c8 71 08 72 48 72 27 48 00 78 40 1e 26 49 

			08 70 eb e0 25 48 00 68 25 49 88 42 01 da 00 24 07 e0 22 49 09 68 22 4a 88 1a 0a 21 ff f7 04 f9 

			04 46 60 06 c0 0f 10 49 c8 70 a0 06 c0 0f 08 71 e0 06 c0 0f 48 71 20 07 c0 0f 88 71 60 07 c0 0f 

			c8 71 a0 07 c0 0f 08 72 e0 07 c0 0f 48 72 c5 e0 1c 01 00 20 14 01 00 20 1e 01 00 20 5c 01 00 20 

			5b 01 00 20 1d 01 00 20 7c 01 00 20 20 01 00 20 21 01 00 20 23 01 00 20 26 01 00 20 28 01 00 20 

			2a 01 00 20 24 01 00 20 00 01 00 20 13 01 00 20 31 01 00 20 5a 01 00 20 54 01 00 20 0c 01 00 20 

			4c 0d 00 00 03 21 49 03 05 20 00 03 02 f0 9a f8 78 49 08 70 08 46 00 78 02 28 03 d1 01 20 76 49 

			08 71 0a e0 73 48 00 78 01 28 03 d1 72 49 08 71 48 71 02 e0 01 20 70 49 48 71 7f e0 6f 48 00 78 

			40 06 c0 0f 6c 49 c8 70 6c 48 00 78 80 06 c0 0f 08 71 6a 48 00 78 c0 06 c0 0f 48 71 67 48 00 78 

			00 07 c0 0f 88 71 65 48 00 78 40 07 c0 0f c8 71 62 48 00 78 80 07 c0 0f 08 72 60 48 00 78 c0 07 

			c0 0f 48 72 00 20 5e 49 08 70 5c 48 00 78 64 21 48 43 ff 30 2d 30 5b 49 08 80 0a 20 5a 49 08 70 

			4c e0 5a 48 00 78 00 28 07 d0 00 20 58 49 08 70 56 48 00 78 40 1e 55 49 08 70 55 48 00 78 4e 49 

			c8 70 01 20 48 71 39 e0 03 20 52 49 08 70 01 20 49 49 08 71 88 71 31 e0 18 e0 ff e7 4e 48 00 78 

			00 28 03 d0 4d 48 00 78 00 28 00 d1 26 e0 4a 48 00 78 40 1e 48 49 08 70 06 20 49 49 08 70 00 f0 

			1d fe 48 49 08 70 00 f0 4f f9 17 e0 46 48 00 78 40 1c 46 49 08 70 44 48 00 78 80 1c 44 49 08 70 

			44 48 00 78 34 49 c8 70 43 48 00 78 08 71 43 48 00 78 48 71 42 48 00 78 88 71 00 bf 00 bf 2e 49 

			40 4a 12 78 88 5c 01 f0 9f fd 3e 48 00 78 40 1c 3c 49 08 70 08 46 00 78 09 28 49 dd 04 20 00 f0 

			77 fa 01 f0 7b fd 00 20 36 49 08 70 36 49 08 70 36 49 08 70 27 48 00 78 00 28 05 d0 25 48 00 78 

			40 1e 24 49 08 70 33 e0 25 48 00 78 00 28 05 d0 23 48 00 78 40 1e 22 49 08 70 29 e0 23 48 00 78 

			00 28 0a d0 21 48 00 78 40 1e 20 49 08 70 20 48 00 78 40 1e 1e 49 08 70 1a e0 25 48 00 78 02 28 

			02 d0 04 28 13 d1 0a e0 0a 48 00 78 01 28 05 d1 0f 48 00 78 01 28 01 d1 00 f0 78 fd 07 e0 01 20 

			0e 49 08 70 00 f0 aa fd 1a 49 08 70 00 bf 00 bf 00 bf ef e4 68 01 00 20 7c 01 00 20 55 01 00 20 

			54 01 00 20 5e 01 00 20 60 01 00 20 5c 01 00 20 12 01 00 20 20 01 00 20 22 01 00 20 2e 01 00 20 

			23 01 00 20 30 01 00 20 04 01 00 20 24 01 00 20 25 01 00 20 06 01 00 20 07 01 00 20 08 01 00 20 

			09 01 00 20 1d 01 00 20 1c 01 00 20 1f 01 00 20 1e 01 00 20 2f 01 00 20 10 b5 4c 48 00 78 08 28 

			0b da 00 f0 49 fd 4a 49 48 4a 12 78 88 54 47 48 00 78 40 1c 45 49 08 70 10 bd 44 48 00 78 08 28 

			40 d1 09 20 41 49 08 70 01 f0 f6 fc 40 48 00 78 01 28 18 d1 3e 48 40 78 00 28 14 d1 3c 48 80 78 

			01 28 10 d1 3a 48 c0 78 c0 00 39 49 09 79 89 00 08 43 37 49 49 79 49 00 08 43 35 49 89 79 08 43 

			34 49 08 70 1e e0 32 48 40 78 01 28 18 d1 30 48 80 78 00 28 14 d1 2e 48 c0 78 01 28 10 d1 2c 48 

			00 79 c0 00 2a 49 49 79 89 00 08 43 28 49 89 79 49 00 08 43 26 49 c9 79 08 43 26 49 08 70 bb e7 

			01 f0 32 fd 24 48 00 78 00 28 21 d1 01 20 23 49 88 70 00 20 c8 70 08 71 48 71 88 71 c8 71 08 72 

			48 72 1c 48 00 78 04 28 02 d0 06 28 0c d1 07 e0 1b 48 00 78 19 49 c8 70 01 20 c8 71 48 72 06 e0 

			01 20 16 49 c8 70 02 e0 01 f0 0e fd 00 bf 00 bf 12 49 11 4a 12 78 88 5c 01 f0 96 fc 0e 48 00 78 

			40 1c 0d 49 08 70 08 46 00 78 09 28 0b dd 04 20 00 f0 6e f9 01 f0 72 fc 00 20 07 49 08 70 03 49 

			08 70 08 49 08 70 00 bf 76 e7 00 00 1c 01 00 20 14 01 00 20 1e 01 00 20 1d 01 00 20 7c 01 00 20 

			12 01 00 20 1f 01 00 20 28 48 00 78 40 02 28 49 09 78 49 00 08 43 27 49 08 80 24 48 00 78 40 06 

			c0 0f 25 49 48 71 21 48 00 78 80 06 c0 0f c8 72 1e 48 00 78 c0 06 c0 0f 08 72 1c 48 00 78 00 07 

			c0 0f 08 74 19 48 00 78 40 07 c0 0f 88 73 17 48 00 78 80 07 c0 0f 48 73 14 48 00 78 c0 07 c0 0f 

			c8 71 13 48 00 78 40 06 c0 0f c8 70 10 48 00 78 80 06 c0 0f 08 73 0e 48 00 78 c0 06 c0 0f 08 71 

			0b 48 00 78 00 07 c0 0f 88 72 09 48 00 78 40 07 c0 0f 48 72 06 48 00 78 80 07 c0 0f c8 73 04 48 

			00 78 c0 07 c0 0f 88 71 70 47 00 00 2f 01 00 20 30 01 00 20 28 01 00 20 7c 01 00 20 03 48 00 88 

			03 49 08 40 01 49 08 80 70 47 00 00 26 01 00 20 fe fe 00 00 70 b5 04 46 01 20 00 03 84 42 06 d1 

			00 f0 fe fe 20 46 01 f0 1b f8 05 46 22 e0 01 20 40 03 84 42 06 d1 00 f0 f3 fe 20 46 01 f0 10 f8 

			05 46 17 e0 07 20 00 03 84 42 0c d1 00 f0 e8 fe 20 46 01 f0 05 f8 05 46 4b 21 c9 00 28 46 01 f0 

			8d fe 05 46 06 e0 20 46 00 f0 da fe 20 46 00 f0 f7 ff 05 46 28 46 70 bd 70 47 70 47 38 b5 04 46 

			6a 46 02 21 20 46 ff f7 3f fa 69 46 48 78 00 02 09 78 08 43 05 b2 06 2c 02 d1 02 48 28 18 05 b2 

			28 46 38 bd 55 f5 ff ff 7c b5 11 a0 00 68 01 90 01 aa 02 21 3e 20 ff f7 32 fa 00 f0 94 f8 6a 46 

			04 21 40 20 ff f7 20 fa 68 46 40 78 01 02 68 46 00 78 01 43 0c 46 68 46 c0 78 00 02 69 46 89 78 

			08 43 05 46 ac 42 01 da 28 46 7c bd 20 46 fc e7 71 00 00 00 10 b5 01 20 00 03 ff f7 8b ff 04 46 

			12 49 ff f7 cd f8 10 d3 01 20 40 03 ff f7 82 ff 04 46 0e 49 ff f7 c4 f8 07 d3 00 20 ff f7 7a ff 

			04 46 0a 49 ff f7 bc f8 05 d2 09 48 00 78 40 1c 07 49 08 70 02 e0 00 20 05 49 08 70 04 48 00 78 

			09 28 01 dd 01 20 10 bd 00 20 fc e7 00 00 53 43 59 01 00 20 10 b5 04 46 00 2c 02 d0 00 20 00 f0 

			35 fe 01 22 11 46 80 20 01 f0 f8 f8 00 2c 02 d0 01 20 00 f0 2b fe 10 bd 10 b5 04 46 00 2c 02 d0 

			00 20 00 f0 23 fe 01 22 11 46 40 20 01 f0 e6 f8 00 2c 02 d0 01 20 00 f0 19 fe 10 bd 10 b5 00 24 

			00 bf 03 e0 00 f0 05 f8 60 1c c4 b2 19 2c f9 db 10 bd 10 b5 00 f0 17 f8 00 f0 15 f8 00 f0 13 f8 

			00 f0 11 f8 10 bd 10 b5 00 24 0a 24 03 e0 00 f0 0a f8 60 1e c4 b2 00 2c f9 dc 10 bd 10 b5 03 20 

			ff f7 56 f9 10 bd 10 b5 22 20 ff f7 51 f9 10 bd 70 b5 04 46 25 46 03 e0 ff f7 f5 ff 68 1e c5 b2 

			00 2d f9 dc 70 bd 70 47 8a b0 00 20 09 90 00 26 00 27 08 90 07 90 06 90 05 90 04 90 03 90 02 90 

			e1 20 40 01 fe 49 08 80 c3 20 80 00 fd 49 08 80 fd 48 fe 49 08 60 fe 49 08 60 0a 20 fd 49 08 70 

			ee e2 01 f0 d9 fd fc 48 00 68 00 28 3e d1 58 20 01 f0 a2 fb 05 46 f9 48 00 78 00 28 31 d1 1f 2d 

			05 d1 00 f0 03 fb 01 20 f4 49 08 70 1c e0 00 2d 02 d1 01 f0 41 fb 17 e0 0c 2d 04 da e8 48 00 88 

			ef 49 88 42 02 dd 3f 20 01 90 0d e0 02 2d 07 db 0b 2d 05 dc 68 1c 81 00 40 18 c0 b2 01 90 03 e0 

			01 2d 01 d1 0f 20 01 90 e6 48 00 78 00 28 08 d1 e5 48 02 78 e5 48 00 78 01 99 01 f0 e1 fa e1 49 

			08 70 7d 20 00 01 dc 49 08 60 a6 e2 d7 48 00 68 00 28 70 d1 0c 20 ff f7 d1 fe 07 46 dc 48 87 42 

			0b dd ff f7 70 ff 0c 20 ff f7 c8 fe 07 46 d8 48 87 42 02 dd 59 20 01 f0 ef fa 3c 46 00 bf cf 48 

			00 78 00 28 73 d1 d3 48 84 42 0a da 08 98 40 1c c0 b2 08 90 08 98 03 28 05 dd 54 20 01 f0 dc fa 

			01 e0 00 20 08 90 cc 48 84 42 0a dd 04 98 40 1c c0 b2 04 90 04 98 07 28 05 dd 59 20 01 f0 cc fa 

			01 e0 00 20 04 90 c5 48 00 78 01 28 53 d1 c4 48 00 68 c4 49 88 42 02 dd 05 20 07 90 25 e0 c0 48 

			00 68 23 21 c9 01 88 42 02 dd 04 20 07 90 1c e0 bb 48 00 68 bb 49 14 39 88 42 02 dd 03 20 07 90 

			13 e0 b7 48 00 68 b7 49 1e 39 88 42 02 dd 02 20 07 90 0a e0 b2 48 00 68 b2 49 28 39 88 42 02 dd 

			01 20 07 90 01 e0 00 20 07 90 af 48 84 42 03 dd 00 20 06 90 7a e0 c0 e0 ab 48 64 38 84 42 02 dd 

			01 20 06 90 72 e0 a8 48 c8 38 84 42 02 dd 02 20 06 90 6b e0 a5 48 84 42 02 dd 03 20 06 90 65 e0 

			a2 48 64 38 84 42 03 dd 04 20 06 90 5e e0 9b e0 05 20 06 90 5a e0 99 48 00 78 02 28 52 d1 98 48 

			00 68 98 49 88 42 02 dd 05 20 07 90 25 e0 94 48 00 68 23 21 c9 01 88 42 02 dd 04 20 07 90 1c e0 

			8f 48 00 68 8f 49 14 39 88 42 02 dd 03 20 07 90 13 e0 8b 48 00 68 8b 49 1e 39 88 42 02 dd 02 20 

			07 90 0a e0 86 48 00 68 86 49 28 39 88 42 02 dd 01 20 07 90 01 e0 00 20 07 90 83 48 c8 30 84 42 

			02 dd 00 20 06 90 21 e0 7f 48 64 30 84 42 02 dd 01 20 06 90 1a e0 7c 48 84 42 02 dd 02 20 06 90 

			14 e0 79 48 64 38 84 42 02 dd 03 20 06 90 0d e0 76 48 64 30 84 42 02 dd 04 20 06 90 06 e0 05 20 

			06 90 03 e0 00 20 07 90 05 20 06 90 06 99 07 98 40 18 05 28 0a dd 03 98 40 1c c0 b2 03 90 03 98 

			05 28 05 dd 5a 20 01 f0 07 fa 01 e0 00 20 03 90 67 48 00 88 84 42 11 dd 65 48 00 88 65 49 88 42 

			0c dd 65 48 00 78 00 28 05 d0 63 48 00 78 40 1e 61 49 08 70 02 e0 55 20 01 f0 ee f9 58 48 00 68 

			58 49 24 39 88 42 10 dd 19 20 c0 01 84 42 0c dd 48 48 00 78 40 1e 47 49 08 70 08 46 00 78 00 28 

			06 d1 55 20 01 f0 d8 f9 02 e0 0a 20 41 49 08 70 7d 20 c0 00 3d 49 08 60 6f e1 50 48 00 68 00 28 

			6c d1 ff f7 b1 fd 06 46 4d 48 86 42 03 dc 7d 20 00 01 86 42 0e da ff f7 36 fe ff f7 a5 fd 06 46 

			47 48 86 42 03 dc 7d 20 00 01 86 42 02 da 59 20 01 f0 b2 f9 3a 48 06 60 30 48 00 78 00 28 4e d1 

			28 48 00 88 00 28 07 d1 30 48 00 78 3f 28 1e dd 3f 20 2e 49 08 70 1a e0 22 48 00 88 ff 21 2d 31 

			88 42 07 da 29 48 00 78 3f 28 10 dd 3f 20 27 49 08 70 0c e0 1b 48 00 88 ff 21 e1 31 88 42 06 da 

			22 48 00 78 32 28 02 dd 32 20 20 49 08 70 2d 48 00 78 00 28 19 d1 22 48 00 68 22 49 28 39 88 42 

			07 dd 1a 48 00 78 3f 28 0f dd 3f 20 17 49 08 70 0b e0 1b 48 00 68 24 49 88 42 06 dd 13 48 00 78 

			3f 28 02 dd 3f 20 11 49 08 70 15 48 00 68 1e 49 64 31 88 42 40 dd 0d 48 00 78 37 e0 91 e0 88 e0 

			36 01 00 20 38 01 00 20 20 4e 00 00 40 01 00 20 4c 01 00 20 61 01 00 20 44 01 00 20 31 01 00 20 

			1e 1c 00 00 54 01 00 20 2d 01 00 20 56 01 00 20 10 27 00 00 30 f8 ff ff 4c 1d 00 00 0a 01 00 20 

			0c 01 00 20 8a 11 00 00 b6 03 00 00 8a 02 00 00 5e 01 00 20 fc 08 00 00 60 01 00 20 3c 01 00 20 

			88 13 00 00 57 01 00 20 68 10 00 00 3f 28 1d dd 3f 20 64 49 08 70 19 e0 63 48 00 68 21 21 c9 01 

			88 42 07 dd 5f 48 00 78 3f 28 0f dd 3f 20 5d 49 08 70 0b e0 5c 48 00 68 5c 49 88 42 06 dd 59 48 

			00 78 3f 28 02 dd 3f 20 56 49 08 70 58 48 00 78 00 28 09 d1 57 48 02 78 57 48 01 78 51 48 00 78 

			01 f0 ce f8 52 49 08 70 54 48 00 78 02 28 08 d1 4d 48 00 68 4d 49 d2 31 88 42 02 dd 5a 20 01 f0 

			eb f8 49 48 00 68 4e 49 88 42 02 dd 5a 20 01 f0 e3 f8 45 48 00 68 4a 49 49 1f 88 42 0a dd 09 98 

			40 1c c0 b2 09 90 09 98 05 28 05 dd 5a 20 01 f0 d3 f8 01 e0 00 20 09 90 ff 20 f5 30 41 49 08 60 

			6b e0 41 48 00 68 00 28 1f d1 06 20 ff f7 96 fc 04 46 3e 48 00 78 00 28 12 d1 00 2c 03 dd ff 20 

			f5 30 84 42 0a dd 05 98 40 1c c0 b2 05 90 05 98 02 28 05 dd 5c 20 01 f0 af f8 01 e0 00 20 05 90 

			ff 20 f5 30 30 49 08 60 47 e0 31 48 00 68 00 28 1e d1 2e 48 00 78 00 28 0e d1 ff f7 ab fc 00 28 

			05 d0 00 20 00 f0 62 f8 01 20 28 49 08 70 19 20 40 01 27 49 08 60 30 e0 02 98 00 28 04 d1 5d 20 

			01 f0 ea f8 01 20 02 90 22 48 21 49 08 60 24 e0 21 48 00 78 00 28 20 d1 20 48 00 88 00 28 06 d1 

			1a 48 00 78 00 28 02 d1 5a 20 01 f0 75 f8 1c 48 00 78 00 28 03 d0 59 20 01 f0 6e f8 0a e0 19 48 

			00 78 00 28 03 d1 18 48 00 78 01 28 02 dd 54 20 01 f0 62 f8 14 20 10 49 08 70 2f 20 ff f7 e8 fc 

			0f e5 00 00 56 01 00 20 0c 01 00 20 7c 10 00 00 54 01 00 20 2d 01 00 20 2c 01 00 20 62 01 00 20 

			8f 11 00 00 3c 01 00 20 4c 01 00 20 31 01 00 20 50 01 00 20 10 27 00 00 48 01 00 20 36 01 00 20 

			13 01 00 20 10 01 00 20 5d 01 00 20 00 28 03 d0 05 49 06 4a 51 60 03 e0 01 21 09 04 03 4a 51 60 

			03 49 08 70 70 47 00 00 01 00 01 00 00 00 05 50 63 01 00 20 70 47 00 00 01 49 48 7c 70 47 00 00 

			40 00 03 50 10 b5 20 20 00 f0 84 fd 04 46 20 46 10 bd 00 00 03 48 00 78 00 28 01 d1 01 20 70 47 

			00 20 fc e7 63 01 00 20 10 b5 03 20 40 03 00 f0 bb fc 01 49 08 60 10 bd 64 01 00 20 10 b5 00 20 

			00 f0 10 ff c4 b2 64 06 64 0e 20 46 10 bd 10 b5 00 21 08 46 00 f0 7a fd 10 bd 00 00 08 b5 01 21 

			68 46 01 70 00 21 41 70 02 21 81 70 01 21 c1 70 fe f7 12 fe 01 20 40 07 f2 49 48 60 f2 48 f3 49 

			88 60 00 f0 6d fa 01 f0 43 f9 00 f0 6a fa ff f7 de ff 00 20 ff f7 20 fc 01 20 00 f0 47 fa 53 20 

			01 f0 b2 f8 05 46 2d 07 2d 0f 00 2d 01 d1 0a 24 11 e0 01 2d 01 d1 3c 24 0d e0 02 2d 01 d1 82 24 

			09 e0 03 2d 01 d1 aa 24 05 e0 04 2d 02 d1 ff 24 05 34 00 e0 0a 24 32 2c 0b db 78 2c 09 da dc 48 

			dc 49 08 60 04 20 dc 49 08 70 02 20 db 49 08 70 37 e0 78 2c 0b db a0 2c 09 da d9 48 d5 49 08 60 

			06 20 d5 49 08 70 01 20 d6 49 08 70 29 e0 a0 2c 0d db ff 20 5f 30 84 42 09 da d3 48 cd 49 08 60 

			06 20 cd 49 08 70 01 20 ce 49 08 70 19 e0 ff 20 5f 30 84 42 0d db ff 20 af 30 84 42 09 da cb 48 

			c4 49 08 60 06 20 c4 49 08 70 02 20 c5 49 08 70 07 e0 c7 48 bf 49 08 60 02 20 bf 49 08 70 bf 49 

			08 70 bd 49 08 78 c1 0f 09 18 49 10 c1 4a 11 70 10 46 00 78 08 21 08 40 c0 10 bf 49 08 70 10 46 

			00 78 04 21 08 40 80 10 bc 49 08 70 10 46 00 78 02 21 08 40 40 10 ba 49 08 70 10 46 00 78 c0 07 

			c0 0f b8 49 08 70 00 f0 71 ff 00 f0 86 ff 00 f0 d5 fe 00 f0 a3 fe 00 20 ff f7 7c fb 00 bf ff f7 

			d2 fb 00 f0 92 ff 00 28 f9 d0 01 f0 bf f9 15 e0 01 f0 c2 f9 ac 48 00 78 00 28 01 d0 00 f0 3c ff 

			aa 48 00 78 01 28 04 d1 a9 48 00 78 01 28 00 d1 05 e0 a8 48 00 78 00 28 00 d1 00 e0 e8 e7 00 bf 

			01 20 a5 49 08 70 ff f7 e7 fa 52 20 00 f0 74 ff 05 46 01 20 a1 49 08 70 00 2d 01 d1 00 f0 1c ff 

			01 f0 9a f9 5e 20 00 f0 67 ff 05 46 02 2d 01 d0 00 f0 12 ff 01 f0 90 f9 ff f7 60 fb 01 f0 8c f9 

			97 48 00 78 00 f0 58 ff 05 46 02 2d 01 d0 00 f0 03 ff 01 f0 81 f9 01 f0 7f f9 91 48 00 78 00 28 

			03 d0 ff f7 d1 fa 8f 49 08 60 ff f7 47 fb 8c 48 00 78 00 28 03 d0 2c 20 ff f7 b0 fa c6 b2 55 2e 

			27 dd ff 20 5f 30 84 42 05 db 14 20 86 49 08 70 86 49 08 70 8e e0 a0 2c 05 db 0f 20 82 49 08 70 

			82 49 08 70 86 e0 78 2c 05 db 0a 20 7e 49 08 70 7e 49 08 70 7e e0 32 2c 05 db 0a 20 7a 49 08 70 

			7a 49 08 70 76 e0 0a 20 77 49 08 70 77 49 08 70 70 e0 4b 2e 27 dd ff 20 5f 30 84 42 05 db 1e 20 

			71 49 08 70 71 49 08 70 64 e0 a0 2c 05 db 19 20 6d 49 08 70 6d 49 08 70 5c e0 78 2c 05 db 14 20 

			69 49 08 70 69 49 08 70 54 e0 32 2c 05 db 0a 20 65 49 08 70 65 49 08 70 4c e0 0a 20 62 49 08 70 

			62 49 08 70 46 e0 32 2e 27 dd ff 20 5f 30 84 42 05 db 28 20 5c 49 08 70 5c 49 08 70 3a e0 a0 2c 

			05 db 28 20 58 49 08 70 58 49 08 70 32 e0 78 2c 05 db 1e 20 54 49 08 70 54 49 08 70 2a e0 32 2c 

			05 db 0f 20 50 49 08 70 50 49 08 70 22 e0 0f 20 4d 49 08 70 4d 49 08 70 1c e0 a0 2c 05 db 3f 20 

			49 49 08 70 49 49 08 70 14 e0 78 2c 05 db 32 20 45 49 08 70 45 49 08 70 0c e0 32 2c 05 db 19 20 

			41 49 08 70 41 49 08 70 04 e0 14 20 3e 49 08 70 3e 49 08 70 ff f7 a2 fa ff f7 36 fe 58 20 00 f0 

			9b fe 01 20 3a 49 08 70 32 48 00 78 00 28 24 d1 22 e0 01 f0 c1 f8 37 48 00 68 00 28 0a d1 58 20 

			00 f0 8a fe 00 28 01 d1 00 f0 36 fe 32 48 31 49 08 60 11 e0 31 48 00 78 00 28 0d d1 22 48 00 78 

			00 28 03 d1 25 48 00 78 01 28 02 dd 54 20 00 f0 13 fe 14 20 29 49 08 70 db e7 0c e0 01 f0 9c f8 

			19 48 00 78 00 28 03 d1 1c 48 00 78 01 28 02 dd 54 20 00 f0 01 fe ff f7 ed fd 01 28 ee d0 ff f7 

			93 fa 00 00 00 00 02 50 07 00 47 00 00 00 05 50 4e 32 00 21 00 01 00 20 04 01 00 20 62 01 00 20 

			6a 32 00 21 0a 01 00 20 94 32 00 21 be 32 00 21 40 32 00 21 05 01 00 20 06 01 00 20 07 01 00 20 

			08 01 00 20 09 01 00 20 10 01 00 20 2a 01 00 20 25 01 00 20 5b 01 00 20 2b 01 00 20 5d 01 00 20 

			21 01 00 20 0c 01 00 20 55 01 00 20 56 01 00 20 12 01 00 20 44 01 00 20 70 17 00 00 48 01 00 20 

			70 b5 02 46 00 29 0a d1 15 4d 16 4e b5 60 ff 25 2d 04 15 43 14 4e 35 43 12 4e 35 60 13 e0 01 29 

			11 d1 d5 06 ed 0e 60 26 16 40 76 00 35 43 2a 46 0b 4d 6d 1c 0b 4e b5 60 ff 25 2d 04 15 43 0a 4e 

			35 43 08 4e 35 60 07 4d ac 68 01 e0 05 4d ac 68 e5 05 ed 0f 00 2d f9 d0 02 4d 6b 68 d8 b2 70 bd 

			01 00 0f 00 00 00 03 40 00 80 00 80 00 28 09 d0 0a 49 09 78 00 29 05 d1 00 bf 62 b6 00 bf 07 49 

			08 70 0a e0 00 28 08 d1 04 49 09 78 00 29 04 d0 00 bf 72 b6 00 bf 01 49 08 70 70 47 6a 01 00 20 

			70 47 10 b5 ff f7 46 fd 00 f0 1a fd 00 f0 ef fc 00 f0 f4 fc 00 f0 c2 fc ff f7 2f f9 10 bd 00 00 

			f1 b5 82 b0 02 98 01 90 05 21 09 03 01 98 88 42 2b d1 01 20 80 05 85 49 08 60 01 21 13 20 ff f7 

			8f ff 07 46 01 21 12 20 ff f7 8a ff 06 46 38 02 30 43 07 46 38 46 fe f7 ec f9 47 21 09 06 00 90 

			fe f7 0c f8 7a 49 08 60 01 21 11 20 ff f7 78 ff 04 46 01 21 10 20 ff f7 73 ff 05 46 21 02 29 43 

			0c 46 20 b2 73 49 08 80 de e0 03 21 49 03 01 98 88 42 2b d1 01 20 40 05 6c 49 08 60 01 21 17 20 

			ff f7 5e ff 07 46 01 21 16 20 ff f7 59 ff 06 46 38 02 30 43 07 46 38 46 fe f7 bb f9 47 21 09 06 

			00 90 fd f7 db ff 62 49 08 60 01 21 15 20 ff f7 47 ff 04 46 01 21 14 20 ff f7 42 ff 05 46 21 02 

			29 43 0c 46 20 b2 5b 49 08 80 ad e0 07 21 09 03 01 98 88 42 4e d1 01 21 1b 20 ff f7 31 ff 07 46 

			01 21 1a 20 ff f7 2c ff 06 46 38 02 30 43 07 46 38 46 fe f7 8e f9 47 21 09 06 00 90 fd f7 ae ff 

			4b 49 08 60 01 21 19 20 ff f7 1a ff 04 46 01 21 18 20 ff f7 15 ff 05 46 20 02 28 43 04 46 20 b2 

			44 49 08 80 01 21 1f 20 ff f7 0a ff 07 46 01 21 1e 20 ff f7 05 ff 06 46 38 02 30 43 07 46 38 46 

			fe f7 67 f9 47 21 09 06 00 90 fd f7 87 ff 3a 49 08 60 01 21 1d 20 ff f7 f3 fe 04 46 01 21 1c 20 

			ff f7 ee fe 05 46 20 02 28 43 04 46 20 b2 33 49 08 80 59 e0 01 21 c9 03 01 98 88 42 27 d1 01 21 

			23 20 ff f7 dd fe 07 46 01 21 22 20 ff f7 d8 fe 06 46 38 02 30 43 07 46 38 46 fe f7 3a f9 47 21 

			09 06 00 90 fd f7 5a ff 21 49 08 60 01 21 21 20 ff f7 c6 fe 04 46 01 21 20 20 ff f7 c1 fe 05 46 

			21 02 29 43 0c 46 20 b2 1a 49 08 80 2c e0 01 21 0f 20 ff f7 b5 fe 07 46 01 21 0e 20 ff f7 b0 fe 

			06 46 38 02 30 43 07 46 38 46 fe f7 12 f9 47 21 09 06 00 90 fd f7 32 ff 0d 49 08 60 01 21 0d 20 

			ff f7 9e fe 04 46 01 21 0c 20 ff f7 99 fe 05 46 21 02 29 43 0c 46 20 b2 06 49 08 80 7d 20 c0 00 

			84 42 01 dd 0b 20 08 80 fe bd 00 00 00 00 06 50 6c 01 00 20 74 01 00 20 70 01 00 20 76 01 00 20 

			f1 b5 8c b0 05 20 09 90 0c 9c 6a 48 6a 49 08 60 0f 20 00 07 20 43 08 60 68 48 80 89 c0 05 c0 0f 

			01 21 48 40 05 90 65 48 80 89 40 04 c0 0f 04 90 0b e0 62 48 80 89 c0 05 c0 0f 01 21 48 40 05 90 

			5e 48 80 89 40 04 c0 0f 04 90 05 98 00 28 f0 d0 04 98 00 28 ed d0 20 46 00 f0 e4 f8 0b 90 00 27 

			00 20 0a 90 19 e0 56 48 53 49 08 60 00 bf 52 48 00 68 02 21 08 40 00 28 f9 d1 4f 48 80 68 01 b2 

			0a 98 40 00 06 aa 11 52 0a 98 40 00 06 a9 08 5e c7 19 0a 98 40 1c c0 b2 0a 90 09 99 0a 98 88 42 

			e1 db 05 21 38 46 fd f7 0f fe 07 46 3f b2 07 20 00 03 84 42 1d d1 43 48 87 42 1a dd 42 49 00 20 

			08 5e fe f7 7b f8 3a b2 02 90 0b 99 50 1a fe f7 75 f8 00 90 3d 48 01 68 00 98 fd f7 62 fe 01 90 

			02 99 fd f7 05 fe 03 90 fe f7 7a f8 05 46 0e 46 18 e0 37 49 00 20 08 5e fe f7 60 f8 02 90 0b 99 

			78 1a fe f7 5b f8 00 90 32 48 01 68 00 98 fd f7 48 fe 01 90 02 99 fd f7 eb fd 03 90 fe f7 60 f8 

			05 46 0e 46 05 20 00 03 84 42 07 d0 03 20 40 03 84 42 03 d0 07 20 00 03 84 42 14 d1 00 22 26 4b 

			28 46 31 46 fd f7 5a ff 00 22 24 4b 01 91 00 90 fd f7 bc ff 00 22 20 4b 03 91 02 90 fd f7 9c fe 

			05 46 0e 46 20 e0 01 20 c0 03 84 42 0e d1 00 22 1b 4b 28 46 31 46 fd f7 41 ff 00 22 17 4b 03 91 

			02 90 fd f7 a3 ff 05 46 0e 46 0d e0 00 22 15 4b 28 46 31 46 fd f7 32 ff 00 22 10 4b 03 91 02 90 

			fd f7 94 ff 05 46 0e 46 28 46 31 46 fe f7 2c f8 0d b0 f0 bd 01 00 01 00 00 00 06 50 00 00 05 50 

			02 00 02 00 77 37 00 00 76 01 00 20 70 01 00 20 74 01 00 20 6c 01 00 20 00 70 a7 40 00 00 e0 40 

			00 00 59 40 00 c0 a2 40 10 b5 01 46 0b 46 0a 48 0a 4c 20 60 0f 20 00 07 18 43 20 60 00 22 08 48 

			20 60 00 bf 05 48 00 68 02 24 20 40 00 28 f9 d1 02 48 82 68 10 b2 10 bd 01 00 01 00 00 00 06 50 

			02 00 02 00 01 46 05 22 12 03 91 42 07 d0 03 22 52 03 91 42 03 d0 07 22 12 03 91 42 03 d1 0c 4a 

			0c 4b 1a 60 02 e0 0c 4a 0a 4b 1a 60 0b 4a 09 4b 1a 60 00 bf 07 4a 12 68 02 23 1a 40 00 2a f9 d1 

			04 4a 92 68 10 b2 03 22 52 06 02 4b 1a 60 70 47 00 04 00 04 00 00 06 50 00 02 00 02 02 00 02 00 

			01 49 08 73 70 47 00 00 40 00 03 50 04 49 09 78 09 02 01 43 02 4a 12 78 11 43 08 46 70 47 00 00 

			40 00 03 50 70 b5 0b 46 14 46 00 2b 05 d0 11 4d 2d 79 05 43 0f 4e 35 71 1b e0 05 04 05 43 0e 4e 

			35 60 0c 4d 2d 79 85 43 0a 4e 35 71 00 21 0e e0 01 25 8d 40 05 40 00 2d 08 d0 4a 00 25 46 95 40 

			03 26 96 40 36 04 35 43 03 4e 75 60 49 1c 07 29 ee db 70 bd 00 00 03 50 40 00 02 50 10 b5 14 4b 

			1b 7d 83 43 12 4c 23 75 00 29 04 d0 23 46 1b 7e 03 43 23 76 04 e0 0e 4b 1b 7e 83 43 0c 4c 23 76 

			00 2a 05 d0 0a 4b 1b 7f 03 43 09 4c 23 77 04 e0 07 4b 1b 7f 83 43 06 4c 23 77 ff 23 04 4c 20 34 

			23 72 03 4b 1b 7c 03 43 01 4c 23 74 10 bd 00 00 20 00 03 50 01 46 04 48 00 7c 08 40 00 28 01 d0 

			01 20 70 47 00 20 fc e7 40 00 03 50 00 29 05 d0 05 4a 12 78 02 43 04 4b 1a 70 04 e0 02 4a 12 78 

			82 43 01 4b 1a 70 70 47 00 00 03 50 f8 b5 06 46 0c 46 19 48 19 49 08 63 00 12 48 63 0a 20 fe f7 

			40 f8 01 20 00 06 15 49 08 63 00 12 48 63 0a 20 fe f7 37 f8 07 27 3f 06 00 2e 11 d1 03 25 2d 02 

			00 2c 03 d1 0e 48 0f 49 48 60 0b e0 01 2c 03 d1 0d 48 0c 49 48 60 05 e0 0b 48 0a 49 48 60 01 e0 

			ff 25 01 35 01 20 c0 05 06 49 08 60 38 46 28 43 06 49 48 60 f8 bd 00 00 00 01 00 01 00 00 01 50 

			08 00 08 00 00 00 02 40 01 00 01 00 00 00 02 50 f8 b5 04 46 0d 46 16 46 1f 46 01 20 3b 46 32 46 

			29 46 00 90 20 46 00 f0 01 f8 f8 bd ff b5 81 b0 0d 46 16 46 1f 46 3c 46 1c e0 20 2c 13 dd 20 23 

			32 46 29 46 01 98 00 f0 17 f8 00 28 02 d0 01 20 05 b0 f0 bd 20 36 20 3c 0a 98 00 28 0a d0 28 46 

			20 30 c5 b2 06 e0 23 46 32 46 29 46 01 98 00 f0 03 f8 ed e7 e1 e7 00 00 ff b5 0d 46 00 98 40 06 

			06 0e 20 2b 02 dd 01 20 04 b0 f0 bd 28 02 30 43 28 4f 38 60 28 48 29 4f 38 60 02 20 38 61 00 bf 

			26 48 00 6a 02 28 fb d1 01 20 30 43 21 4f 38 60 21 48 22 4f 38 60 01 20 38 61 00 bf 1f 48 00 6a 

			01 28 fb d1 1e 48 1d 4f 38 60 38 46 43 61 00 bf 1a 48 00 6a 98 42 fb d1 19 48 14 38 17 4f 38 60 

			00 24 15 e0 17 48 a7 10 bf 00 c1 59 11 70 52 1c ff 20 00 02 08 40 00 0a 10 70 52 1c ff 20 00 04 

			08 40 00 0c 10 70 52 1c 08 0e 10 70 52 1c 24 1d 9c 42 e7 db 00 bf 09 48 c0 69 20 27 38 40 20 28 

			f9 d1 00 20 c0 43 05 4f f8 61 07 48 38 60 00 20 aa e7 00 00 00 01 02 40 09 00 ff 00 00 00 02 40 

			25 00 7f 00 00 02 02 40 00 00 ff 07 f8 b5 04 46 0d 46 16 46 1f 46 01 20 3b 46 32 46 29 46 00 90 

			20 46 00 f0 01 f8 f8 bd ff b5 81 b0 0d 46 16 46 1f 46 3c 46 1c e0 1e 2c 13 dd 1e 23 32 46 29 46 

			01 98 00 f0 17 f8 00 28 02 d0 01 20 05 b0 f0 bd 1e 36 1e 3c 0a 98 00 28 0a d0 28 46 1e 30 c5 b2 

			06 e0 23 46 32 46 29 46 01 98 00 f0 03 f8 ed e7 e1 e7 00 00 ff b5 81 b0 0d 46 01 98 40 06 00 0e 

			00 90 00 26 1c 46 1e 2b 01 dc 00 2b 02 d1 01 20 05 b0 f0 bd 28 02 00 9f 38 43 01 46 10 78 52 1c 

			00 04 01 43 01 2b 03 d0 10 78 52 1c 00 06 01 43 24 48 01 60 02 2c 27 dd a4 1e 14 e0 24 1f 00 21 

			11 78 52 1c 10 78 52 1c 00 02 01 43 10 78 52 1c 00 04 01 43 10 78 52 1c 00 06 01 43 19 48 00 1d 

			b7 00 c1 51 76 1c 04 2c e8 dc 10 78 57 78 3f 02 38 43 97 78 3f 04 38 43 d7 78 3f 06 38 43 01 46 

			10 48 00 1d b7 00 c1 51 0f 48 10 4f 38 60 98 1c 38 61 00 bf 0d 48 00 6a 9f 1c b8 42 fa d1 0a 48 

			08 30 0a 4f 38 60 00 bf 08 48 c0 69 20 27 38 40 20 28 f9 d1 00 20 c0 43 04 4f f8 61 04 48 38 60 

			00 20 a5 e7 00 01 02 40 09 00 ff 00 00 00 02 40 00 00 ff 01 42 01 02 4b d1 18 01 22 8a 61 70 47 

			00 00 04 50 01 46 48 01 01 4b c2 18 90 68 70 47 00 00 04 50 10 b5 01 46 01 20 4b 01 02 4c 1a 19 

			13 69 18 40 10 bd 00 00 00 00 04 50 30 b5 03 46 5c 01 05 4d 60 19 01 60 00 2a 02 d0 04 24 04 61 

			01 e0 00 24 04 61 30 bd 00 00 04 50 42 01 03 4b d1 18 0a 69 01 23 1a 43 0a 61 70 47 00 00 04 50 

			76 20 01 49 c8 60 70 47 00 00 01 40 0a 4a 50 60 00 22 09 4b 1a 60 00 29 05 d0 1a 46 12 68 02 23 

			1a 43 05 4b 1a 60 04 4a 12 68 01 23 1a 43 02 4b 1a 60 76 22 da 60 70 47 00 00 01 40 10 b5 07 48 

			07 49 88 60 00 22 11 46 80 20 ff f7 ab fd 00 22 11 46 01 20 ff f7 a6 fd 10 bd 00 00 01 00 01 00 

			40 00 02 50 10 b5 00 22 01 21 80 20 ff f7 9a fd 10 bd 10 b5 04 46 00 2c 04 d0 01 21 80 20 ff f7 

			f5 fd 03 e0 00 21 80 20 ff f7 f0 fd 10 bd 10 b5 02 22 00 21 40 20 ff f7 85 fd 10 bd 03 48 04 49 

			88 60 00 20 03 49 48 71 70 47 00 00 10 00 10 00 40 00 02 50 00 00 03 50 00 20 02 49 48 70 01 20 

			48 71 70 47 00 00 03 50 00 28 03 d0 01 21 03 4a 51 70 02 e0 00 21 01 4a 51 70 70 47 00 00 03 50 

			10 b5 01 22 00 21 20 20 ff f7 5c fd 10 bd 10 b5 00 21 20 20 ff f7 ba fd 00 22 01 21 20 20 ff f7 

			51 fd 10 bd 10 b5 04 46 00 2c 04 d0 01 21 20 20 ff f7 ac fd 03 e0 00 21 20 20 ff f7 a7 fd 10 bd 

			30 b5 03 46 10 48 04 78 10 48 00 78 98 42 01 dd 0e 48 03 70 0e 48 01 70 0e 48 02 70 91 42 00 da 

			0a 46 0a 48 00 78 90 42 02 dd 07 48 02 70 03 e0 06 48 00 78 04 4d 28 70 03 48 00 78 84 42 01 d0 

			05 20 30 bd 00 20 fc e7 55 01 00 20 56 01 00 20 2c 01 00 20 2d 01 00 20 10 b5 04 46 00 f0 8c fa 

			00 20 fe f7 c3 ff ff f7 89 ff 20 46 00 f0 54 f8 00 f0 02 f8 10 bd 00 00 01 48 02 49 08 60 70 47 

			b9 fd 00 00 40 00 01 50 10 b5 07 48 00 78 02 28 09 d0 05 48 00 78 01 28 03 d1 02 20 02 49 08 70 

			01 e0 ff f7 e9 ff 10 bd 5d 01 00 20 10 b5 00 24 ff f7 48 ff 00 bf 0d e0 00 20 ff f7 4a ff 01 20 

			fe f7 56 fc 01 20 ff f7 44 ff 03 20 fe f7 50 fc 60 1c c4 b2 1e 2c ef db 10 bd 08 b5 03 21 68 46 

			01 70 00 21 41 70 03 21 81 70 01 21 c1 70 fd f7 e3 fd 01 22 7d 21 c9 01 00 20 ff f7 d7 fe 08 bd 

			10 b5 00 20 ff f7 e2 fe 10 bd 10 b5 00 20 ff f7 c1 fe 04 46 20 46 10 bd fe b5 05 46 00 27 00 f0 

			2b fa 01 95 00 20 3e 49 08 70 ff f7 50 ff fe f7 15 fc 00 20 ff f7 56 ff fe f7 f0 fb 01 20 ff f7 

			51 ff 00 24 1f e0 37 48 00 78 00 28 03 d0 58 2d 01 d1 ff f7 13 ff 00 f0 0f fa 00 bf 30 48 00 78 

			00 28 fb d0 00 f0 08 fa 06 20 01 1b 01 98 08 41 c0 07 c0 0f 00 90 00 98 ff f7 34 ff 00 20 28 49 

			08 70 60 1c c4 b2 07 2c dd db 00 f0 f5 f9 00 24 28 e0 24 48 00 78 00 28 03 d0 58 2d 01 d1 ff f7 

			ed fe 00 f0 e9 f9 00 bf 1d 48 00 78 00 28 fb d0 00 f0 e2 f9 00 2c 03 d1 ff f7 02 ff fe f7 ce fb 

			00 20 17 49 08 70 fe f7 2d ff 06 46 06 2c 07 d0 00 2c 05 d0 05 20 01 1b 30 46 88 40 38 43 c7 b2 

			60 1c c4 b2 07 2c d4 db 00 f0 c6 f9 00 bf 0c 48 00 78 00 28 fb d0 00 f0 bf f9 ff f7 e8 fe fe f7 

			ad fb 00 20 ff f7 ee fe 00 20 05 49 08 70 fe f7 85 fb fe f7 83 fb 00 f0 af f9 38 46 fe bd 00 00 

			11 01 00 20 10 01 00 20 fe b5 05 46 00 27 00 f0 a3 f9 01 95 00 20 3c 49 08 70 ff f7 c8 fe fe f7 

			8d fb 00 20 ff f7 ce fe fe f7 68 fb 01 20 ff f7 c9 fe 00 24 1f e0 35 48 00 78 00 28 03 d0 58 2d 

			01 d1 ff f7 8b fe 00 f0 87 f9 00 bf 2e 48 00 78 00 28 fb d0 00 f0 80 f9 06 20 01 1b 01 98 08 41 

			c0 07 c0 0f 00 90 00 98 ff f7 ac fe 00 20 26 49 08 70 60 1c c4 b2 07 2c dd db 00 f0 6d f9 00 24 

			24 e0 22 48 00 78 00 28 03 d0 58 2d 01 d1 ff f7 65 fe 00 f0 61 f9 00 bf 1b 48 00 78 00 28 fb d0 

			00 f0 5a f9 00 2c 03 d1 ff f7 7a fe fe f7 46 fb 00 20 15 49 08 70 fe f7 a5 fe 06 46 06 20 01 1b 

			30 46 88 40 38 43 c7 b2 60 1c c4 b2 07 2c d8 db 00 f0 42 f9 00 bf 0c 48 00 78 00 28 fb d0 00 f0 

			3b f9 ff f7 64 fe fe f7 29 fb 00 20 ff f7 6a fe 00 20 05 49 08 70 fe f7 01 fb fe f7 ff fa 00 f0 

			2b f9 38 46 fe bd 00 00 11 01 00 20 10 01 00 20 00 20 2a 49 08 70 2a 49 08 70 2a 49 08 70 2a 49 

			08 70 01 20 29 49 08 70 00 20 48 70 88 70 28 49 08 70 28 49 08 70 28 49 08 70 28 49 08 70 03 20 

			27 49 08 70 00 20 27 49 08 70 27 49 08 70 27 49 08 70 27 49 08 80 40 1e 26 49 08 80 00 20 26 49 

			08 70 26 49 08 70 3f 20 25 49 08 70 25 49 08 70 00 20 25 49 08 70 25 49 08 70 25 49 08 70 3f 20 

			24 49 08 70 24 49 08 70 01 20 24 49 08 70 24 49 08 70 00 20 23 49 08 70 23 49 08 70 02 20 23 49 

			08 70 03 20 22 49 08 70 00 20 22 49 08 70 22 49 08 70 22 49 08 70 22 49 08 70 70 47 10 01 00 20 

			12 01 00 20 13 01 00 20 1c 01 00 20 7c 01 00 20 1d 01 00 20 1f 01 00 20 20 01 00 20 21 01 00 20 

			22 01 00 20 23 01 00 20 24 01 00 20 25 01 00 20 26 01 00 20 28 01 00 20 2a 01 00 20 2b 01 00 20 

			2c 01 00 20 2d 01 00 20 2e 01 00 20 31 01 00 20 54 01 00 20 55 01 00 20 56 01 00 20 57 01 00 20 

			58 01 00 20 59 01 00 20 5a 01 00 20 5b 01 00 20 5c 01 00 20 5d 01 00 20 62 01 00 20 63 01 00 20 

			0a 01 00 20 f8 b5 05 46 00 24 00 26 00 27 28 46 ff f7 aa fa 04 46 1c 48 00 68 24 1a 1b 48 00 68 

			e1 21 09 01 88 42 01 da 19 4e 77 00 17 48 00 68 18 49 88 42 02 da 16 4e 77 00 1b e0 13 48 00 68 

			14 49 64 31 88 42 02 da 11 4e 77 00 12 e0 0f 48 00 68 7d 21 49 01 88 42 02 da 0d 4e 77 00 09 e0 

			0a 48 00 68 0c 49 88 42 02 da 09 4e 77 00 01 e0 07 4e 77 00 b4 42 01 da 00 20 f8 bd bc 42 01 dd 

			02 20 fa e7 01 20 f8 e7 64 01 00 20 0c 01 00 20 22 02 00 00 74 0e 00 00 04 10 00 00 fe b5 06 46 

			0c 46 01 21 44 20 fe f7 eb ff 02 90 02 98 04 28 13 d1 15 48 00 68 fd f7 41 fa 13 49 01 90 09 68 

			08 19 fd f7 3b fa 31 46 00 90 fd f7 2a f8 07 46 01 99 fd f7 63 f8 05 46 14 e0 0b 48 00 68 fd f7 

			2d fa 09 49 01 90 09 68 09 19 08 46 c8 38 fd f7 25 fa 31 46 00 90 fd f7 14 f8 07 46 01 99 fd f7 

			4d f8 05 46 28 46 fe bd 78 01 00 20 10 b5 01 21 00 20 ff f7 bb fc 10 bd 10 b5 ff f7 b1 fc 10 bd 

			00 00 00 01 00 01 00 01 00 00 01 01 01 00 00 00 01 00 01 00 01 01 00 00 01 01 01 00 00 00 00 01 

			00 01 00 01 01 00 00 01 01 00 00 01 00 01 00 00 00 01 00 00 01 01 01 00 00 00 01 01 01 00 00 01 

			01 00 01 00 00 01 00 00 00 01 00 01 01 01 01 00 01 01 00 00 00 01 00 01 00 00 00 01 00 01 00 00 

			01 00 00 00 01 01 01 00 01 01 01 00 01 00 00 01 00 00 00 01 00 01 01 01 01 00 01 01 00 00 00 01 

			00 01 00 00 00 01 00 01 00 00 01 00 00 00 01 01 01 00 01 01 01 00 01 00 00 01 00 00 00 01 01 00 

			00 01 01 00 01 01 00 00 f8 32 00 21 00 01 00 20 7c 00 00 00 76 0b 00 21 00 00 00 00 00 00 00 00 

			00 00 00 00 00 00 00 00 00 00 00 00 00 00 00 00 00 00 00 00 00 00 00 00 00 00 00 00 00 00 00 00 

			00 00 00 00 00 00 00 00 00 00 00 00 00 00 00 00 00 00 00 00 00 00 00 00 00 00 00 00 00 00 00 00 

			00 00 00 00 00 00 00 00 00 00 00 00 00 00 00 00 00 00 00 00 00 00 00 00 00 00 00 00 00 00 00 00 

			00 00 00 00 00 00 00 00 00 00 00 00 00 00 00 00 00 00 00 00 00 00 00 00 00 00 00 00 00 00 00 00 

			00 00 00 00 00 00 00 00 00 00 00 00 00 00 00 00 00 00 00 00 00 00 00 00 00 00 00 00 00 00 00 00 

			00 00 00 00 00 00 00 00 00 00 00 00 00 00 00 00 00 00 00 00 00 02 00 06 04 05 03 fe d5 34 55 34 
		];
	};
};

&pio {
	charger_pins_default: eint0default {
	};

	charger_pins_eint_output0: charger_gpio_as_output_low {		//check
		pins_cmd_dat {
			pinmux = <PINMUX_GPIO192__FUNC_GPIO192>;
			slew-rate = <1>;
			output-low;
		};
	};

	charger_pins_eint_output1: charger_gpio_as_output_high {	//check
		pins_cmd_dat {
			pinmux = <PINMUX_GPIO192__FUNC_GPIO192>;
			slew-rate = <1>;
			output-high;
		};
	};

	ship_sleep_gpio: ship_sleep {
		pins_cmd_dat {
			pinmux = <PINMUX_GPIO126__FUNC_GPIO126>;		//check
			slew-rate = <1>;
			output-low;
		};
	};

	ship_active_gpio: ship_active {
		pins_cmd_dat {
			pinmux = <PINMUX_GPIO126__FUNC_GPIO126>;		//check
			slew-rate = <1>;
			output-high;
		};
	};

	dischg_enable: dischg_enable {
		pins_cmd_dat {
			pinmux = <PINMUX_GPIO51__FUNC_GPIO51>;		//check
			slew-rate = <1>;							//0:input direction 1:output direction
			bias-pull-up;
			output-high;
		};
	};

	dischg_disable: dischg_disable {
		pins_cmd_dat {
			pinmux = <PINMUX_GPIO51__FUNC_GPIO51>;		//check
			slew-rate = <1>;
			bias-pull-down = <00>;
			output-low;
		};
	};

	vooc_asic_id_active: vooc_asic_id_active {
		pins_cmd_dat {
			pinmux = <PINMUX_GPIO187__FUNC_GPIO187>;
			input-enable;
			slew-rate = <0>;
			bias-pull-up;
		};
	};

	vooc_asic_id_sleep: vooc_asic_id_sleep {
		pins_cmd_dat {
			pinmux = <PINMUX_GPIO187__FUNC_GPIO187>;
			input-enable;
			slew-rate = <0>;
			bias-pull-down;
		};
	};

	ccdetect_active: ccdetect_active {
		pins_cmd_dat {
			pinmux = <PINMUX_GPIO5__FUNC_GPIO5>;
			input-enable;
			slew-rate = <0>;
			bias-disable;
		};
	};
	ccdetect_sleep: ccdetect_sleep {
		pins_cmd_dat {
			pinmux = <PINMUX_GPIO5__FUNC_GPIO5>;
			input-enable;
			slew-rate = <0>;
			bias-disable;
		};
	};
	/*
	shortc_active_gpio: shortc_active {
		pins_cmd_dat {
			pinmux = <PINMUX_GPIO121__FUNC_GPIO121>;
			input-enable;
			slew-rate = <0>;
			bias-pull-up;
		};
	};*/

	//Lukaili Add for camera flash led 
	chgvin_enable: chgvin_enable {
		pins_cmd_dat {
			pinmux = <PINMUX_GPIO30__FUNC_GPIO30>;				//check
			slew-rate = <1>;//0:input direction 1:output direction
			bias-pull-up;
			output-low;
		};
	};

	chgvin_disable: chgvin_disable {
		pins_cmd_dat {
			pinmux = <PINMUX_GPIO30__FUNC_GPIO30>;			//check
			slew-rate = <1>;
			bias-pull-down;
			output-high;
		};
	};

	pmic_chgfunc_enable: pmic_chgfunc_enable {
		pins_cmd_dat {
			pinmux = <PINMUX_GPIO26__FUNC_GPIO26>;			//check
			slew-rate = <1>;//0:input direction 1:output direction
			bias-pull-up;
			output-low;
		};
	};

	pmic_chgfunc_disable: pmic_chgfunc_disable {
		pins_cmd_dat {
			pinmux = <PINMUX_GPIO26__FUNC_GPIO26>;			//check
			slew-rate = <1>;
			bias-pull-down;
			output-high;
		};
	};
	//end Add for camera flash led 
};

&pio {
	charging_switch1_active: charging_switch1_active {
		pins_cmd_dat {
			pinmux = <PINMUX_GPIO191__FUNC_GPIO191>;		//check
			slew-rate = <1>;
			output-high;
		};
	};

	charging_switch1_sleep: charging_switch1_sleep {
		pins_cmd_dat {
			pinmux = <PINMUX_GPIO191__FUNC_GPIO191>;		//check
			slew-rate = <1>;
			output-low;
		};
	};

	charging_switch1_ctr1_active: charging_switch1_ctr1_active {
		pins_cmd_dat {
			pinmux = <PINMUX_GPIO163__FUNC_GPIO163>;		//empty
			slew-rate = <1>;
			bias-pull-up;
		};
	};
	charging_switch1_ctr1_sleep: charging_switch1_ctr1_sleep {
		pins_cmd_dat {
			pinmux = <PINMUX_GPIO163__FUNC_GPIO163>;		//empty
			slew-rate = <1>;
			output-low;
		};
	};
	
	charging_clock_active: charging_clock_active {
		pins_cmd_dat {
			pinmux = <PINMUX_GPIO95__FUNC_GPIO95>;		//check
			slew-rate = <0>;
			bias-pull-up;
		};
	};

	charging_clock_sleep: charging_clock_sleep {
		pins_cmd_dat {
			pinmux = <PINMUX_GPIO95__FUNC_GPIO95>;		//check
			slew-rate = <0>;
			bias-pull-down;
		};
	};

	charging_data_active: charging_data_active {
		pins_cmd_dat {
			pinmux = <PINMUX_GPIO94__FUNC_GPIO94>;		//check
			slew-rate = <0>;
			bias-pull-down;
		};
	};

	charging_data_sleep: charging_data_sleep {
		pins_cmd_dat {
			pinmux = <PINMUX_GPIO94__FUNC_GPIO94>;		//check
			slew-rate = <0>;
			bias-pull-down;
		};
	};

	charging_reset_active: charging_reset_active {
		pins_cmd_dat {
			pinmux = <PINMUX_GPIO189__FUNC_GPIO189>;	//check
			slew-rate = <1>;
			bias-pull-down;
		};
	};

	charging_reset_sleep: charging_reset_sleep {
		pins_cmd_dat {
			pinmux = <PINMUX_GPIO189__FUNC_GPIO189>;	//check
			slew-rate = <1>;
			bias-pull-up;
		};
	};

	mps_otg_en_active: mps_otg_en_active {
		pins_cmd_dat {
			pinmux = <PINMUX_GPIO129__FUNC_GPIO129>;		//check
            slew-rate = <1>;
            bias-pull-up;
		};
	};

	mps_otg_en_sleep: mps_otg_en_sleep {
		pins_cmd_dat {
			pinmux = <PINMUX_GPIO129__FUNC_GPIO129>;		//check
			slew-rate = <1>;
			bias-pull-down;
		};
	};

	mps_otg_en_default: mps_otg_en_default {
		pins_cmd_dat {
			pinmux = <PINMUX_GPIO129__FUNC_GPIO129>;		//check
			slew-rate = <1>;
			bias-pull-down;
		};
	};
};

&mt6360_pmu {
	mt6360,intr_gpio_num = <24>; /* direct defined GPIO num */
	mt6360,intr_gpio = <&pio 24 0x0>;
	disable_lpsd = <1>;
};

&mt6360_pmic {
	pwr_off_seq = [04 00 02 02];
};

&mt6360_typec {
	mt6360pd,intr_gpio_num = <25>; /* direct defined GPIO num */
	mt6360pd,intr_gpio = <&pio 25 0x0>;
};

/* USB SWITCH GPIO start */
//#ifdef OPLUS_ARCH_EXTENDS
//#endif
/*
&pio {
	usb_default: usb_default {
	};

	gpio_redriver_c1_init: c1_init {
		pins_cmd_dat {
			pinmux = <PINMUX_GPIO113__FUNC_GPIO113>;
			slew-rate = <1>;
			output-low;
		};
	};

	gpio_redriver_c1_low: c1_low {
		pins_cmd_dat {
			pinmux = <PINMUX_GPIO113__FUNC_GPIO113>;
			slew-rate = <1>;
			output-low;
		};
	};

	gpio_redriver_c1_hiz: c1_highz {
		pins_cmd_dat {
			pinmux = <PINMUX_GPIO113__FUNC_GPIO113>;
			slew-rate= <0>;
			bias-disable;
		};
	};

	gpio_redriver_c1_high: c1_high {
		pins_cmd_dat {
			pinmux = <PINMUX_GPIO113__FUNC_GPIO113>;
			slew-rate = <1>;
			output-high;
		};
	};

	gpio_redriver_c2_init: c2_init {
		pins_cmd_dat {
			pinmux = <PINMUX_GPIO112__FUNC_GPIO112>;
			slew-rate = <1>;
			output-low;
		};
	};

	gpio_redriver_c2_low: c2_low {
		pins_cmd_dat {
			pinmux = <PINMUX_GPIO112__FUNC_GPIO112>;
			slew-rate = <1>;
			output-low;
		};
	};

	gpio_redriver_c2_hiz: c2_highz {
		pins_cmd_dat {
			pinmux = <PINMUX_GPIO112__FUNC_GPIO112>;
			slew-rate= <0>;
			bias-disable;
		};
	};

	gpio_redriver_c2_high: c2_high {
		pins_cmd_dat {
			pinmux = <PINMUX_GPIO112__FUNC_GPIO112>;
			slew-rate = <1>;
			output-high;
		};
	};

	gpio_u3_switch_sel1: u3_sw_sel1 {
		pins_cmd_dat {
			pinmux = <PINMUX_GPIO111__FUNC_GPIO111>;
			slew-rate = <1>;
			output-low;
		};
	};

	gpio_u3_switch_sel2: u3_sw_sel2 {
		pins_cmd_dat {
			pinmux = <PINMUX_GPIO111__FUNC_GPIO111>;
			slew-rate = <1>;
			output-high;
		};
	};

	gpio_u3_switch_enable: u3_sw_en {
	};

	gpio_u3_switch_disable: u3_sw_dis {
	};
};

&usb_c_pinctrl {
	pinctrl-names = "usb_default",
		"redrv_c1_init",
		"redrv_c1_low",
		"redrv_c1_hiz",
		"redrv_c1_high",
		"redrv_c2_init",
		"redrv_c2_low",
		"redrv_c2_hiz",
		"redrv_c2_high",
		"switch_sel1",
		"switch_sel2",
		"switch_enable",
		"switch_disable";

	pinctrl-0 = <&usb_default>;
	pinctrl-1 = <&gpio_redriver_c1_init>;
	pinctrl-2 = <&gpio_redriver_c1_low>;
	pinctrl-3 = <&gpio_redriver_c1_hiz>;
	pinctrl-4 = <&gpio_redriver_c1_high>;
	pinctrl-5 = <&gpio_redriver_c2_init>;
	pinctrl-6 = <&gpio_redriver_c2_low>;
	pinctrl-7 = <&gpio_redriver_c2_hiz>;
	pinctrl-8 = <&gpio_redriver_c2_high>;
	pinctrl-9 = <&gpio_u3_switch_sel1>;
	pinctrl-10 = <&gpio_u3_switch_sel2>;
	pinctrl-11 = <&gpio_u3_switch_enable>;
	pinctrl-12 = <&gpio_u3_switch_disable>;
	status = "okay";

	usb_switch-data {
		en_pin_num = <0>;
		en_pin_val = <0>;
		sel_pin_num = <111>;
		sel_pin_val = <1>;
		c1_pin_num = <113>;
		c1_pin_val = <2>;
		c2_pin_num = <112>;
		c2_pin_val = <1>;
	};
};
*/
/* USB SWITCH GPIO end */

//#ifdef OPLUS_FEATURE_NFC_BRINGUP
&i2c3 {
       status = "okay";
       nfc_nxp@28 {
               compatible = "nxp,pn544";
               reg = <0x28>;
               nxp,pn544-irq = <&pio 7 0x0>;
               nxp,pn544-ven = <&pio 16 0x0>;
               nxp,pn544-fw-dwnld = <&pio 6 0x0>;
               nxp,pn544-clkreq = <&pio 17 0x0>;
               interrupt-parent = <&pio>;
       };
       nfc_st21@8 {
           compatible = "st,st21nfc";
           reg = <0x8>;
           gpio-irq-std    = <&pio 7 0x0>;
           gpio-rst-std    = <&pio 16 0x0>;
           //gpio-pidle-std  = <&pio 16 0x0>;
           gpio-clkreq-std = <&pio 17 0x0>;
       };
};

&spi5 {
       status = "okay";
       #address-cells = <1>;
       #size-cells = <0>;
       spidev5: p61@5 {
           compatible = "nxp,p61";
           reg = <0>;
           spi-max-frequency = <19200000>;
       };

       st54spi@0 {
           compatible = "st,st54spi";
           reg = <0>;
           spi-max-frequency = <1000000> ;

           gpio-power_nreset = <6>;
           gpio-power_nreset-std = <&pio 6 0x0>;

           power_mode = "ST54H";

           pinctrl-names = "pinctrl_state_mode_idle", "pinctrl_state_mode_spi";
           pinctrl-0 = <&pinctrl_state_mode_idle>;
           pinctrl-1 = <&pinctrl_state_mode_spi>;
           status = "disable";
       };
};
//#endif /* OPLUS_FEATURE_NFC_BRINGUP */

//#ifdef OPLUS_FEATURE_NFC_BRINGUP
&pio {
    pinctrl_state_mode_idle: pinctrl_state_mode_idle {
        pins_cmd0_dat {
            pinmux = <PINMUX_GPIO37__FUNC_GPIO37>;
            input-enable;
            bias-pull-down;
        };
    };

    pinctrl_state_mode_spi: pinctrl_state_mode_spi {
        pins_cmd0_dat {
            pinmux = <PINMUX_GPIO37__FUNC_SPI5_A_CSB>;
            bias-disable;
        };
    };
};
//#endif /* OPLUS_FEATURE_NFC_BRINGUP */

/* GPS GPIO standardization start */
&pio {
	gps_pins_default: gps_default {
	};

	gps_l1_lna_pins_ol: gps_l1_lna@0 {
		pins_cmd_dat {
			pinmux = <PINMUX_GPIO162__FUNC_GPIO162>;
			output-low;
		};
	};
	gps_l1_lna_pins_dsp_ctrl: gps_l1_lna@1 {
		pins_cmd_dat {
			pinmux = <PINMUX_GPIO162__FUNC_GPS_L1_ELNA_EN>;
		};
	};
	gps_l1_lna_pins_oh: gps_l1_lna@2 {
		pins_cmd_dat {
			pinmux = <PINMUX_GPIO162__FUNC_GPIO162>;
			output-high;
		};
	};

	gps_l5_lna_pins_ol: gps_l5_lna@0 {
		pins_cmd_dat {
			pinmux = <PINMUX_GPIO163__FUNC_GPIO163>;
			output-low;
		};
	};
	gps_l5_lna_pins_dsp_ctrl: gps_l5_lna@1 {
		pins_cmd_dat {
			pinmux = <PINMUX_GPIO163__FUNC_GPS_L5_ELNA_EN>;
		};
	};
	gps_l5_lna_pins_oh: gps_l5_lna@2 {
		pins_cmd_dat {
			pinmux = <PINMUX_GPIO163__FUNC_GPIO163>;
			output-high;
		};
	};
};

&gps {
	pinctrl-names = "default",
		"gps_l1_lna_disable",
		"gps_l1_lna_dsp_ctrl",
		"gps_l1_lna_enable",
		"gps_l5_lna_disable",
		"gps_l5_lna_dsp_ctrl",
		"gps_l5_lna_enable";
	pinctrl-0 = <&gps_pins_default>;
	pinctrl-1 = <&gps_l1_lna_pins_ol>;
	pinctrl-2 = <&gps_l1_lna_pins_dsp_ctrl>;
	pinctrl-3 = <&gps_l1_lna_pins_oh>;
	pinctrl-4 = <&gps_l5_lna_pins_ol>;
	pinctrl-5 = <&gps_l5_lna_pins_dsp_ctrl>;
	pinctrl-6 = <&gps_l5_lna_pins_oh>;
	status = "okay";
};
/* GPS GPIO standardization end */

&dsi0 {
	status = "okay";
	#address-cells = <1>;
	#size-cells = <0>;
	/*#ifdef VENDOE_EDIT*/
	panel6@0 {
		compatible = "oplus20645_boe_nt37800_1080p_dsi_cmd";
		reg = <0>;
		pm-enable-gpios = <&pio 41 0>;
		reset-gpios = <&pio 42 0>;
		bias-gpios = <&pio 29 0>;
		ldo3-supply = <&mt_pmic_vmc_ldo_reg>;
		/*pm8008ldo1-supply = <&L1P>;*/
		pinctrl-names = "default";
		port {
			panel_in6: endpoint {
				remote-endpoint = <&dsi_out>;
			};
		};
	};
	panel7@0 {
		compatible = "oplus20645_tianma_nt37701_1080p_dsi_cmd";
		reg = <1>;
		pm-enable-gpios = <&pio 41 0>;
		reset-gpios = <&pio 42 0>;
		bias-gpios = <&pio 29 0>;
		ldo3-supply = <&mt_pmic_vmc_ldo_reg>;
		/*pm8008ldo1-supply = <&L1P>;*/
		pinctrl-names = "default";
		port {
			panel_in7: endpoint {
				remote-endpoint = <&dsi_out>;
			};
		};
	};
	panel8@0 {
		compatible = "oplus20645_samsung_ana6705_1080p_dsi_cmd,lcm";
		reg = <2>;
		pm-enable-gpios = <&pio 41 0>;
		reset-gpios = <&pio 42 0>;
		bias-gpios = <&pio 29 0>;
		ldo3-supply = <&mt_pmic_vmc_ldo_reg>;
		/*pm8008ldo1-supply = <&L1P>;*/
		pinctrl-names = "default";
		port {
			panel_in8: endpoint {
				remote-endpoint = <&dsi_out>;
			};
		};
	};
	panel9@0 {
		compatible = "oplus20645_tianma_nt37701_32_1080p_dsi_cmd";
		reg = <3>;
		pm-enable-gpios = <&pio 41 0>;
		reset-gpios = <&pio 42 0>;
		bias-gpios = <&pio 29 0>;
		ldo3-supply = <&mt_pmic_vmc_ldo_reg>;
		pinctrl-names = "default";
		port {
			panel_in9: endpoint {
				remote-endpoint = <&dsi_out>;
			};
		};
	};
	/*#endif*/
	ports {
		port {
			dsi_out: endpoint {
				remote-endpoint = <&panel_in6>;
			};
		};
	};
};

&odm {
	oplus_devinfo:oplus_devinfo {
		compatible = "oplus-devinfo";
		pinctrl-names = "default", "aboard_gpio0_sleep", "aboard_gpio0_active", "aboard_gpio0_idle";
		pinctrl-0 = <&hw_pins_default>;
		pinctrl-1 = <&aboard_pin_gpio0_sleep>;
		pinctrl-2 = <&aboard_pin_gpio0_active>;
		pinctrl-3 = <&aboard_pin_gpio0_idle>;
		main-sub {
			use_tristate_gpio;
			compatible = "hw-match, main-sub";
			aboard-gpio0 = <&pio 132 0x00>;
			aboard-patterns = <0 0 0 0>;	/*0[high-resistance] 1[pull-down] 2[pull-up]*/
			/*main board*/
			match-projects = <20645 20649 0x2064A 0x2048D>;
		};
	};
};
&pio {
	hw_pins_default:default@hw_sub_id {
	};

	aboard_pin_gpio0_sleep:sleep@id0 {
		pins_cmd_dat {
			pinmux = <PINMUX_GPIO132__FUNC_GPIO132>;
			slew-rate = <0>;
			bias-pull-down;
			input-enable;
		};
	};

	aboard_pin_gpio0_active:active@id0 {
		pins_cmd_dat {
			pinmux = <PINMUX_GPIO132__FUNC_GPIO132>;
			slew-rate = <0>;
			bias-pull-up;
			input-enable;
		};
	};

	aboard_pin_gpio0_idle:idle@id0 {
		pins_cmd_dat {
			pinmux = <PINMUX_GPIO132__FUNC_GPIO132>;
			slew-rate = <0>;
			bias-disable;
			input-enable;
		};
	};
};
/*#endif OPLUS_FEATURE_TP_BASIC*/

//#ifdef OPLUS_FEATURE_CHG_BASIC
&lk_charger{
	charger_by_buckboost;
	support_tuv_authentication;
};

&phy_tuning {
	compatible = "mediatek,phy_tuning";
	u2_vrt_ref = <6>;
	u2_term_ref = <6>;
	u2_enhance = <2>;

	u2_vrt_ref_host = <6>;
	u2_term_ref_host = <6>;
	u2_enhance_host = <1>;
};
//#endif
